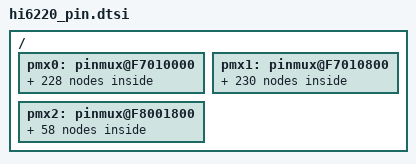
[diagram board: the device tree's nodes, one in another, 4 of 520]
/*****************************************
Generated Time : 2014-07-14-19-44
Author         : s00249479
Tool Version   : V1.0
*****************************************/
/ {
    pmx0: pinmux@F7010000 {
		gpio080_pmx_func: gpio080_pmx_func {
                     pinctrl-single,pins = <0x0    0x0>;
		};
		gpio080_pmx_idle: gpio080_pmx_idle {
                     pinctrl-single,pins = <0x0    0x0>;
		};

		PMU_SSI_pmx_func: PMU_SSI_pmx_func {
                     pinctrl-single,pins = <0x4    0x0>;
		};
		PMU_SSI_pmx_idle: PMU_SSI_pmx_idle {
                     pinctrl-single,pins = <0x4    0x0>;
		};

		gpio066_pmx_func: gpio066_pmx_func {
                     pinctrl-single,pins = <0x8    0x0>;
		};
		gpio066_pmx_idle: gpio066_pmx_idle {
                     pinctrl-single,pins = <0x8    0x1>;
		};

		gpio067_pmx_func: gpio067_pmx_func {
                     pinctrl-single,pins = <0xC    0x0>;
		};
		gpio067_pmx_idle: gpio067_pmx_idle {
                     pinctrl-single,pins = <0xC    0x1>;
		};

		gpio068_pmx_func: gpio068_pmx_func {
                     pinctrl-single,pins = <0x10    0x0>;
		};
		gpio068_pmx_idle: gpio068_pmx_idle {
                     pinctrl-single,pins = <0x10    0x1>;
		};

		gpio069_pmx_func: gpio069_pmx_func {
                     pinctrl-single,pins = <0x14    0x0>;
		};
		gpio069_pmx_idle: gpio069_pmx_idle {
                     pinctrl-single,pins = <0x14    0x1>;
		};

		gpio070_pmx_func: gpio070_pmx_func {
                     pinctrl-single,pins = <0x18    0x0>;
		};
		gpio070_pmx_idle: gpio070_pmx_idle {
                     pinctrl-single,pins = <0x18    0x1>;
		};

		gpio071_pmx_func: gpio071_pmx_func {
                     pinctrl-single,pins = <0x1C    0x0>;
		};
		gpio071_pmx_idle: gpio071_pmx_idle {
                     pinctrl-single,pins = <0x1C    0x1>;
		};

		gpio072_pmx_func: gpio072_pmx_func {
                     pinctrl-single,pins = <0x20    0x0>;
		};
		gpio072_pmx_idle: gpio072_pmx_idle {
                     pinctrl-single,pins = <0x20    0x1>;
		};

		gpio073_pmx_func: gpio073_pmx_func {
                     pinctrl-single,pins = <0x24    0x0>;
		};
		gpio073_pmx_idle: gpio073_pmx_idle {
                     pinctrl-single,pins = <0x24    0x0>;
		};

		gpio074_pmx_func: gpio074_pmx_func {
                     pinctrl-single,pins = <0x28    0x0>;
		};
		gpio074_pmx_idle: gpio074_pmx_idle {
                     pinctrl-single,pins = <0x28    0x0>;
		};

		gpio075_pmx_func: gpio075_pmx_func {
                     pinctrl-single,pins = <0x2C    0x0>;
		};
		gpio075_pmx_idle: gpio075_pmx_idle {
                     pinctrl-single,pins = <0x2C    0x0>;
		};

		gpio076_pmx_func: gpio076_pmx_func {
                     pinctrl-single,pins = <0x30    0x1>;
		};
		gpio076_pmx_idle: gpio076_pmx_idle {
                     pinctrl-single,pins = <0x30    0x1>;
		};

		gpio077_pmx_func: gpio077_pmx_func {
                     pinctrl-single,pins = <0x34    0x1>;
		};
		gpio077_pmx_idle: gpio077_pmx_idle {
                     pinctrl-single,pins = <0x34    0x1>;
		};

		gpio078_pmx_func: gpio078_pmx_func {
                     pinctrl-single,pins = <0x38    0x1>;
		};
		gpio078_pmx_idle: gpio078_pmx_idle {
                     pinctrl-single,pins = <0x38    0x1>;
		};

		gpio079_pmx_func: gpio079_pmx_func {
                     pinctrl-single,pins = <0x3C    0x0>;
		};
		gpio079_pmx_idle: gpio079_pmx_idle {
                     pinctrl-single,pins = <0x3C    0x0>;
		};

		gpio081_pmx_func: gpio081_pmx_func {
                     pinctrl-single,pins = <0x40    0x0>;
		};
		gpio081_pmx_idle: gpio081_pmx_idle {
                     pinctrl-single,pins = <0x40    0x0>;
		};

		gpio082_pmx_func: gpio082_pmx_func {
                     pinctrl-single,pins = <0x44    0x0>;
		};
		gpio082_pmx_idle: gpio082_pmx_idle {
                     pinctrl-single,pins = <0x44    0x0>;
		};

		gpio083_pmx_func: gpio083_pmx_func {
                     pinctrl-single,pins = <0x48    0x0>;
		};
		gpio083_pmx_idle: gpio083_pmx_idle {
                     pinctrl-single,pins = <0x48    0x0>;
		};

		gpio084_pmx_func: gpio084_pmx_func {
                     pinctrl-single,pins = <0x4C    0x1>;
		};
		gpio084_pmx_idle: gpio084_pmx_idle {
                     pinctrl-single,pins = <0x4C    0x1>;
		};

		gpio085_pmx_func: gpio085_pmx_func {
                     pinctrl-single,pins = <0x50    0x1>;
		};
		gpio085_pmx_idle: gpio085_pmx_idle {
                     pinctrl-single,pins = <0x50    0x1>;
		};

		gpio086_pmx_func: gpio086_pmx_func {
                     pinctrl-single,pins = <0x54    0x0>;
		};
		gpio086_pmx_idle: gpio086_pmx_idle {
                     pinctrl-single,pins = <0x54    0x0>;
		};

		gpio087_pmx_func: gpio087_pmx_func {
                     pinctrl-single,pins = <0x58    0x0>;
		};
		gpio087_pmx_idle: gpio087_pmx_idle {
                     pinctrl-single,pins = <0x58    0x0>;
		};

		gpio088_pmx_func: gpio088_pmx_func {
                     pinctrl-single,pins = <0x5C    0x0>;
		};
		gpio088_pmx_idle: gpio088_pmx_idle {
                     pinctrl-single,pins = <0x5C    0x0>;
		};

		gpio089_pmx_func: gpio089_pmx_func {
                     pinctrl-single,pins = <0x60    0x0>;
		};
		gpio089_pmx_idle: gpio089_pmx_idle {
                     pinctrl-single,pins = <0x60    0x0>;
		};

		gpio090_pmx_func: gpio090_pmx_func {
                     pinctrl-single,pins = <0x64    0x1>;
		};
		gpio090_pmx_idle: gpio090_pmx_idle {
                     pinctrl-single,pins = <0x64    0x1>;
		};

		HKADC_SSI_pmx_func: HKADC_SSI_pmx_func {
                     pinctrl-single,pins = <0x68    0x0>;
		};
		HKADC_SSI_pmx_idle: HKADC_SSI_pmx_idle {
                     pinctrl-single,pins = <0x68    0x0>;
		};

		CODEC_CLK_pmx_func: CODEC_CLK_pmx_func {
                     pinctrl-single,pins = <0x6C    0x0>;
		};
		CODEC_CLK_pmx_idle: CODEC_CLK_pmx_idle {
                     pinctrl-single,pins = <0x6C    0x0>;
		};

		gpio091_pmx_func: gpio091_pmx_func {
                     pinctrl-single,pins = <0x70    0x1>;
		};
		gpio091_pmx_idle: gpio091_pmx_idle {
                     pinctrl-single,pins = <0x70    0x1>;
		};

		gpio092_pmx_func: gpio092_pmx_func {
                     pinctrl-single,pins = <0x74    0x0>;
		};
		gpio092_pmx_idle: gpio092_pmx_idle {
                     pinctrl-single,pins = <0x74    0x0>;
		};

		gpio093_pmx_func: gpio093_pmx_func {
                     pinctrl-single,pins = <0x78    0x0>;
		};
		gpio093_pmx_idle: gpio093_pmx_idle {
                     pinctrl-single,pins = <0x78    0x0>;
		};

		gpio094_pmx_func: gpio094_pmx_func {
                     pinctrl-single,pins = <0x7C    0x0>;
		};
		gpio094_pmx_idle: gpio094_pmx_idle {
                     pinctrl-single,pins = <0x7C    0x0>;
		};

		gpio095_pmx_func: gpio095_pmx_func {
                     pinctrl-single,pins = <0x80    0x1>;
		};
		gpio095_pmx_idle: gpio095_pmx_idle {
                     pinctrl-single,pins = <0x80    0x1>;
		};

		gpio096_pmx_func: gpio096_pmx_func {
                     pinctrl-single,pins = <0x84    0x1>;
		};
		gpio096_pmx_idle: gpio096_pmx_idle {
                     pinctrl-single,pins = <0x84    0x1>;
		};

		gpio097_pmx_func: gpio097_pmx_func {
                     pinctrl-single,pins = <0x88    0x1>;
		};
		gpio097_pmx_idle: gpio097_pmx_idle {
                     pinctrl-single,pins = <0x88    0x1>;
		};

		gpio098_pmx_func: gpio098_pmx_func {
                     pinctrl-single,pins = <0x8C    0x1>;
		};
		gpio098_pmx_idle: gpio098_pmx_idle {
                     pinctrl-single,pins = <0x8C    0x1>;
		};

		BT_XCLK_pmx_func: BT_XCLK_pmx_func {
                     pinctrl-single,pins = <0x90    0x0>;
		};
		BT_XCLK_pmx_idle: BT_XCLK_pmx_idle {
                     pinctrl-single,pins = <0x90    0x0>;
		};

		BT_XFS_pmx_func: BT_XFS_pmx_func {
                     pinctrl-single,pins = <0x94    0x0>;
		};
		BT_XFS_pmx_idle: BT_XFS_pmx_idle {
                     pinctrl-single,pins = <0x94    0x0>;
		};

		BT_DI_pmx_func: BT_DI_pmx_func {
                     pinctrl-single,pins = <0x98    0x0>;
		};
		BT_DI_pmx_idle: BT_DI_pmx_idle {
                     pinctrl-single,pins = <0x98    0x0>;
		};

		BT_DO_pmx_func: BT_DO_pmx_func {
                     pinctrl-single,pins = <0x9C    0x0>;
		};
		BT_DO_pmx_idle: BT_DO_pmx_idle {
                     pinctrl-single,pins = <0x9C    0x0>;
		};

		gpio102_pmx_func: gpio102_pmx_func {
                     pinctrl-single,pins = <0xB8    0x1>;
		};
		gpio102_pmx_idle: gpio102_pmx_idle {
                     pinctrl-single,pins = <0xB8    0x1>;
		};

		gpio103_pmx_func: gpio103_pmx_func {
                     pinctrl-single,pins = <0xBC    0x1>;
		};
		gpio103_pmx_idle: gpio103_pmx_idle {
                     pinctrl-single,pins = <0xBC    0x1>;
		};

		gpio104_pmx_func: gpio104_pmx_func {
                     pinctrl-single,pins = <0xC0    0x0>;
		};
		gpio104_pmx_idle: gpio104_pmx_idle {
                     pinctrl-single,pins = <0xC0    0x0>;
		};

		gpio105_pmx_func: gpio105_pmx_func {
                     pinctrl-single,pins = <0xC4    0x0>;
		};
		gpio105_pmx_idle: gpio105_pmx_idle {
                     pinctrl-single,pins = <0xC4    0x0>;
		};

		gpio106_pmx_func: gpio106_pmx_func {
                     pinctrl-single,pins = <0xC8    0x0>;
		};
		gpio106_pmx_idle: gpio106_pmx_idle {
                     pinctrl-single,pins = <0xC8    0x0>;
		};

		gpio107_pmx_func: gpio107_pmx_func {
                     pinctrl-single,pins = <0xCC    0x0>;
		};
		gpio107_pmx_idle: gpio107_pmx_idle {
                     pinctrl-single,pins = <0xCC    0x0>;
		};

		gpio108_pmx_func: gpio108_pmx_func {
                     pinctrl-single,pins = <0xD0    0x0>;
		};
		gpio108_pmx_idle: gpio108_pmx_idle {
                     pinctrl-single,pins = <0xD0    0x0>;
		};

		gpio109_pmx_func: gpio109_pmx_func {
                     pinctrl-single,pins = <0xD4    0x0>;
		};
		gpio109_pmx_idle: gpio109_pmx_idle {
                     pinctrl-single,pins = <0xD4    0x0>;
		};

		gpio110_pmx_func: gpio110_pmx_func {
                     pinctrl-single,pins = <0xD8    0x0>;
		};
		gpio110_pmx_idle: gpio110_pmx_idle {
                     pinctrl-single,pins = <0xD8    0x0>;
		};

		gpio111_pmx_func: gpio111_pmx_func {
                     pinctrl-single,pins = <0xDC    0x0>;
		};
		gpio111_pmx_idle: gpio111_pmx_idle {
                     pinctrl-single,pins = <0xDC    0x0>;
		};

		gpio112_pmx_func: gpio112_pmx_func {
                     pinctrl-single,pins = <0xE0    0x0>;
		};
		gpio112_pmx_idle: gpio112_pmx_idle {
                     pinctrl-single,pins = <0xE0    0x0>;
		};

		gpio113_pmx_func: gpio113_pmx_func {
                     pinctrl-single,pins = <0xE4    0x0>;
		};
		gpio113_pmx_idle: gpio113_pmx_idle {
                     pinctrl-single,pins = <0xE4    0x0>;
		};

		gpio114_pmx_func: gpio114_pmx_func {
                     pinctrl-single,pins = <0xE8    0x0>;
		};
		gpio114_pmx_idle: gpio114_pmx_idle {
                     pinctrl-single,pins = <0xE8    0x0>;
		};

		gpio115_pmx_func: gpio115_pmx_func {
                     pinctrl-single,pins = <0xEC    0x0>;
		};
		gpio115_pmx_idle: gpio115_pmx_idle {
                     pinctrl-single,pins = <0xEC    0x0>;
		};

		gpio116_pmx_func: gpio116_pmx_func {
                     pinctrl-single,pins = <0xF0    0x0>;
		};
		gpio116_pmx_idle: gpio116_pmx_idle {
                     pinctrl-single,pins = <0xF0    0x0>;
		};

		gpio117_pmx_func: gpio117_pmx_func {
                     pinctrl-single,pins = <0xF4    0x0>;
		};
		gpio117_pmx_idle: gpio117_pmx_idle {
                     pinctrl-single,pins = <0xF4    0x0>;
		};

		gpio118_pmx_func: gpio118_pmx_func {
                     pinctrl-single,pins = <0xF8    0x0>;
		};
		gpio118_pmx_idle: gpio118_pmx_idle {
                     pinctrl-single,pins = <0xF8    0x0>;
		};

		gpio119_pmx_func: gpio119_pmx_func {
                     pinctrl-single,pins = <0xFC    0x0>;
		};
		gpio119_pmx_idle: gpio119_pmx_idle {
                     pinctrl-single,pins = <0xFC    0x0>;
		};

		EMMC_CLK_pmx_func: EMMC_CLK_pmx_func {
                     pinctrl-single,pins = <0x100    0x0>;
		};
		EMMC_CLK_pmx_idle: EMMC_CLK_pmx_idle {
                     pinctrl-single,pins = <0x100    0x0>;
		};

		EMMC_CMD_pmx_func: EMMC_CMD_pmx_func {
                     pinctrl-single,pins = <0x104    0x0>;
		};
		EMMC_CMD_pmx_idle: EMMC_CMD_pmx_idle {
                     pinctrl-single,pins = <0x104    0x0>;
		};

		EMMC_DATA0_pmx_func: EMMC_DATA0_pmx_func {
                     pinctrl-single,pins = <0x108    0x0>;
		};
		EMMC_DATA0_pmx_idle: EMMC_DATA0_pmx_idle {
                     pinctrl-single,pins = <0x108    0x0>;
		};

		EMMC_DATA1_pmx_func: EMMC_DATA1_pmx_func {
                     pinctrl-single,pins = <0x10C    0x0>;
		};
		EMMC_DATA1_pmx_idle: EMMC_DATA1_pmx_idle {
                     pinctrl-single,pins = <0x10C    0x0>;
		};

		EMMC_DATA2_pmx_func: EMMC_DATA2_pmx_func {
                     pinctrl-single,pins = <0x110    0x0>;
		};
		EMMC_DATA2_pmx_idle: EMMC_DATA2_pmx_idle {
                     pinctrl-single,pins = <0x110    0x0>;
		};

		EMMC_DATA3_pmx_func: EMMC_DATA3_pmx_func {
                     pinctrl-single,pins = <0x114    0x0>;
		};
		EMMC_DATA3_pmx_idle: EMMC_DATA3_pmx_idle {
                     pinctrl-single,pins = <0x114    0x0>;
		};

		EMMC_DATA4_pmx_func: EMMC_DATA4_pmx_func {
                     pinctrl-single,pins = <0x118    0x0>;
		};
		EMMC_DATA4_pmx_idle: EMMC_DATA4_pmx_idle {
                     pinctrl-single,pins = <0x118    0x0>;
		};

		EMMC_DATA5_pmx_func: EMMC_DATA5_pmx_func {
                     pinctrl-single,pins = <0x11C    0x0>;
		};
		EMMC_DATA5_pmx_idle: EMMC_DATA5_pmx_idle {
                     pinctrl-single,pins = <0x11C    0x0>;
		};

		EMMC_DATA6_pmx_func: EMMC_DATA6_pmx_func {
                     pinctrl-single,pins = <0x120    0x0>;
		};
		EMMC_DATA6_pmx_idle: EMMC_DATA6_pmx_idle {
                     pinctrl-single,pins = <0x120    0x0>;
		};

		EMMC_DATA7_pmx_func: EMMC_DATA7_pmx_func {
                     pinctrl-single,pins = <0x124    0x0>;
		};
		EMMC_DATA7_pmx_idle: EMMC_DATA7_pmx_idle {
                     pinctrl-single,pins = <0x124    0x0>;
		};

		gpio120_pmx_func: gpio120_pmx_func {
                     pinctrl-single,pins = <0x128    0x0>;
		};
		gpio120_pmx_idle: gpio120_pmx_idle {
                     pinctrl-single,pins = <0x128    0x1>;
		};

		gpio121_pmx_func: gpio121_pmx_func {
                     pinctrl-single,pins = <0x12C    0x0>;
		};
		gpio121_pmx_idle: gpio121_pmx_idle {
                     pinctrl-single,pins = <0x12C    0x1>;
		};

		gpio122_pmx_func: gpio122_pmx_func {
                     pinctrl-single,pins = <0x130    0x0>;
		};
		gpio122_pmx_idle: gpio122_pmx_idle {
                     pinctrl-single,pins = <0x130    0x1>;
		};

		gpio123_pmx_func: gpio123_pmx_func {
                     pinctrl-single,pins = <0x134    0x0>;
		};
		gpio123_pmx_idle: gpio123_pmx_idle {
                     pinctrl-single,pins = <0x134    0x1>;
		};

		gpio124_pmx_func: gpio124_pmx_func {
                     pinctrl-single,pins = <0x138    0x0>;
		};
		gpio124_pmx_idle: gpio124_pmx_idle {
                     pinctrl-single,pins = <0x138    0x1>;
		};

		gpio125_pmx_func: gpio125_pmx_func {
                     pinctrl-single,pins = <0x13C    0x0>;
		};
		gpio125_pmx_idle: gpio125_pmx_idle {
                     pinctrl-single,pins = <0x13C    0x1>;
		};

		gpio024_pmx_func: gpio024_pmx_func {
                     pinctrl-single,pins = <0x140    0x0>;
		};
		gpio024_pmx_idle: gpio024_pmx_idle {
                     pinctrl-single,pins = <0x140    0x0>;
		};

		gpio025_pmx_func: gpio025_pmx_func {
                     pinctrl-single,pins = <0x144    0x0>;
		};
		gpio025_pmx_idle: gpio025_pmx_idle {
                     pinctrl-single,pins = <0x144    0x0>;
		};

		gpio026_pmx_func: gpio026_pmx_func {
                     pinctrl-single,pins = <0x148    0x0>;
		};
		gpio026_pmx_idle: gpio026_pmx_idle {
                     pinctrl-single,pins = <0x148    0x0>;
		};

		gpio027_pmx_func: gpio027_pmx_func {
                     pinctrl-single,pins = <0x14C    0x0>;
		};
		gpio027_pmx_idle: gpio027_pmx_idle {
                     pinctrl-single,pins = <0x14C    0x0>;
		};

		gpio028_pmx_func: gpio028_pmx_func {
                     pinctrl-single,pins = <0x150    0x1>;
		};
		gpio028_pmx_idle: gpio028_pmx_idle {
                     pinctrl-single,pins = <0x150    0x1>;
		};

		gpio029_pmx_func: gpio029_pmx_func {
                     pinctrl-single,pins = <0x154    0x0>;
		};
		gpio029_pmx_idle: gpio029_pmx_idle {
                     pinctrl-single,pins = <0x154    0x0>;
		};

		gpio030_pmx_func: gpio030_pmx_func {
                     pinctrl-single,pins = <0x158    0x0>;
		};
		gpio030_pmx_idle: gpio030_pmx_idle {
                     pinctrl-single,pins = <0x158    0x0>;
		};

		gpio031_pmx_func: gpio031_pmx_func {
                     pinctrl-single,pins = <0x15C    0x0>;
		};
		gpio031_pmx_idle: gpio031_pmx_idle {
                     pinctrl-single,pins = <0x15C    0x0>;
		};

		gpio032_pmx_func: gpio032_pmx_func {
                     pinctrl-single,pins = <0x160    0x0>;
		};
		gpio032_pmx_idle: gpio032_pmx_idle {
                     pinctrl-single,pins = <0x160    0x0>;
		};

		gpio033_pmx_func: gpio033_pmx_func {
                     pinctrl-single,pins = <0x164    0x0>;
		};
		gpio033_pmx_idle: gpio033_pmx_idle {
                     pinctrl-single,pins = <0x164    0x0>;
		};

		gpio034_pmx_func: gpio034_pmx_func {
                     pinctrl-single,pins = <0x168    0x0>;
		};
		gpio034_pmx_idle: gpio034_pmx_idle {
                     pinctrl-single,pins = <0x168    0x0>;
		};

		gpio035_pmx_func: gpio035_pmx_func {
                     pinctrl-single,pins = <0x16C    0x0>;
		};
		gpio035_pmx_idle: gpio035_pmx_idle {
                     pinctrl-single,pins = <0x16C    0x0>;
		};

		gpio036_pmx_func: gpio036_pmx_func {
                     pinctrl-single,pins = <0x170    0x1>;
		};
		gpio036_pmx_idle: gpio036_pmx_idle {
                     pinctrl-single,pins = <0x170    0x1>;
		};

		gpio037_pmx_func: gpio037_pmx_func {
                     pinctrl-single,pins = <0x174    0x1>;
		};
		gpio037_pmx_idle: gpio037_pmx_idle {
                     pinctrl-single,pins = <0x174    0x1>;
		};

		gpio038_pmx_func: gpio038_pmx_func {
                     pinctrl-single,pins = <0x178    0x1>;
		};
		gpio038_pmx_idle: gpio038_pmx_idle {
                     pinctrl-single,pins = <0x178    0x1>;
		};

		gpio039_pmx_func: gpio039_pmx_func {
                     pinctrl-single,pins = <0x17C    0x0>;
		};
		gpio039_pmx_idle: gpio039_pmx_idle {
                     pinctrl-single,pins = <0x17C    0x0>;
		};

		gpio040_pmx_func: gpio040_pmx_func {
                     pinctrl-single,pins = <0x180    0x0>;
		};
		gpio040_pmx_idle: gpio040_pmx_idle {
                     pinctrl-single,pins = <0x180    0x0>;
		};

		gpio041_pmx_func: gpio041_pmx_func {
                     pinctrl-single,pins = <0x184    0x0>;
		};
		gpio041_pmx_idle: gpio041_pmx_idle {
                     pinctrl-single,pins = <0x184    0x0>;
		};

		gpio042_pmx_func: gpio042_pmx_func {
                     pinctrl-single,pins = <0x188    0x0>;
		};
		gpio042_pmx_idle: gpio042_pmx_idle {
                     pinctrl-single,pins = <0x188    0x0>;
		};

		gpio043_pmx_func: gpio043_pmx_func {
                     pinctrl-single,pins = <0x18C    0x0>;
		};
		gpio043_pmx_idle: gpio043_pmx_idle {
                     pinctrl-single,pins = <0x18C    0x0>;
		};

		gpio044_pmx_func: gpio044_pmx_func {
                     pinctrl-single,pins = <0x190    0x3>;
		};
		gpio044_pmx_idle: gpio044_pmx_idle {
                     pinctrl-single,pins = <0x190    0x3>;
		};

		gpio045_pmx_func: gpio045_pmx_func {
                     pinctrl-single,pins = <0x194    0x0>;
		};
		gpio045_pmx_idle: gpio045_pmx_idle {
                     pinctrl-single,pins = <0x194    0x0>;
		};

		gpio046_pmx_func: gpio046_pmx_func {
                     pinctrl-single,pins = <0x198    0x0>;
		};
		gpio046_pmx_idle: gpio046_pmx_idle {
                     pinctrl-single,pins = <0x198    0x0>;
		};

		gpio047_pmx_func: gpio047_pmx_func {
                     pinctrl-single,pins = <0x19C    0x0>;
		};
		gpio047_pmx_idle: gpio047_pmx_idle {
                     pinctrl-single,pins = <0x19C    0x0>;
		};

		gpio048_pmx_func: gpio048_pmx_func {
                     pinctrl-single,pins = <0x1A0    0x0>;
		};
		gpio048_pmx_idle: gpio048_pmx_idle {
                     pinctrl-single,pins = <0x1A0    0x0>;
		};

		gpio049_pmx_func: gpio049_pmx_func {
                     pinctrl-single,pins = <0x1A4    0x0>;
		};
		gpio049_pmx_idle: gpio049_pmx_idle {
                     pinctrl-single,pins = <0x1A4    0x0>;
		};

		gpio050_pmx_func: gpio050_pmx_func {
                     pinctrl-single,pins = <0x1A8    0x0>;
		};
		gpio050_pmx_idle: gpio050_pmx_idle {
                     pinctrl-single,pins = <0x1A8    0x0>;
		};

		gpio051_pmx_func: gpio051_pmx_func {
                     pinctrl-single,pins = <0x1AC    0x0>;
		};
		gpio051_pmx_idle: gpio051_pmx_idle {
                     pinctrl-single,pins = <0x1AC    0x0>;
		};

		gpio052_pmx_func: gpio052_pmx_func {
                     pinctrl-single,pins = <0x1B0    0x3>;
		};
		gpio052_pmx_idle: gpio052_pmx_idle {
                     pinctrl-single,pins = <0x1B0    0x3>;
		};

		gpio053_pmx_func: gpio053_pmx_func {
                     pinctrl-single,pins = <0x1B4    0x1>;
		};
		gpio053_pmx_idle: gpio053_pmx_idle {
                     pinctrl-single,pins = <0x1B4    0x1>;
		};

		gpio054_pmx_func: gpio054_pmx_func {
                     pinctrl-single,pins = <0x1B8    0x0>;
		};
		gpio054_pmx_idle: gpio054_pmx_idle {
                     pinctrl-single,pins = <0x1B8    0x0>;
		};

		gpio055_pmx_func: gpio055_pmx_func {
                     pinctrl-single,pins = <0x1BC    0x0>;
		};
		gpio055_pmx_idle: gpio055_pmx_idle {
                     pinctrl-single,pins = <0x1BC    0x0>;
		};

		gpio056_pmx_func: gpio056_pmx_func {
                     pinctrl-single,pins = <0x1C0    0x0>;
		};
		gpio056_pmx_idle: gpio056_pmx_idle {
                     pinctrl-single,pins = <0x1C0    0x0>;
		};

		gpio057_pmx_func: gpio057_pmx_func {
                     pinctrl-single,pins = <0x1C4    0x0>;
		};
		gpio057_pmx_idle: gpio057_pmx_idle {
                     pinctrl-single,pins = <0x1C4    0x0>;
		};

		gpio060_pmx_func: gpio060_pmx_func {
                     pinctrl-single,pins = <0x1D0    0x0>;
		};
		gpio060_pmx_idle: gpio060_pmx_idle {
                     pinctrl-single,pins = <0x1D0    0x0>;
		};

		gpio061_pmx_func: gpio061_pmx_func {
                     pinctrl-single,pins = <0x1D4    0x0>;
		};
		gpio061_pmx_idle: gpio061_pmx_idle {
                     pinctrl-single,pins = <0x1D4    0x0>;
		};

		gpio062_pmx_func: gpio062_pmx_func {
                     pinctrl-single,pins = <0x1D8    0x1>;
		};
		gpio062_pmx_idle: gpio062_pmx_idle {
                     pinctrl-single,pins = <0x1D8    0x1>;
		};

		gpio063_pmx_func: gpio063_pmx_func {
                     pinctrl-single,pins = <0x1DC    0x1>;
		};
		gpio063_pmx_idle: gpio063_pmx_idle {
                     pinctrl-single,pins = <0x1DC    0x1>;
		};

		gpio064_pmx_func: gpio064_pmx_func {
                     pinctrl-single,pins = <0x1E0    0x0>;
		};
		gpio064_pmx_idle: gpio064_pmx_idle {
                     pinctrl-single,pins = <0x1E0    0x0>;
		};

		gpio065_pmx_func: gpio065_pmx_func {
                     pinctrl-single,pins = <0x1E4    0x0>;
		};
		gpio065_pmx_idle: gpio065_pmx_idle {
                     pinctrl-single,pins = <0x1E4    0x0>;
		};

       };

    pmx1: pinmux@F7010800 {
		gpio080_cfg_func: gpio080_cfg_func {
                     pinctrl-single,pins = <0x0  0>;
                     pinctrl-single,bias-pulldown = <0 2 0 2>;
                     pinctrl-single,bias-pullup = <1 1 0 1>;
                     pinctrl-single,drive-strength = <0x00 0x70>;
		};
		gpio080_cfg_idle: gpio080_cfg_idle {
                     pinctrl-single,pins = <0x0  0>;
                     pinctrl-single,bias-pulldown = <0 2 0 2>;
                     pinctrl-single,bias-pullup = <1 1 0 1>;
                     pinctrl-single,drive-strength = <0x00 0x70>;
		};

		PMU_SSI_cfg_func: PMU_SSI_cfg_func {
                     pinctrl-single,pins = <0x4  0>;
                     pinctrl-single,bias-pulldown = <0 2 0 2>;
                     pinctrl-single,bias-pullup = <0 1 0 1>;
                     pinctrl-single,drive-strength = <0x00 0x70>;
		};
		PMU_SSI_cfg_idle: PMU_SSI_cfg_idle {
                     pinctrl-single,pins = <0x4  0>;
                     pinctrl-single,bias-pulldown = <0 2 0 2>;
                     pinctrl-single,bias-pullup = <0 1 0 1>;
                     pinctrl-single,drive-strength = <0x00 0x70>;
		};

		gpio066_cfg_func: gpio066_cfg_func {
                     pinctrl-single,pins = <0x8  0>;
                     pinctrl-single,bias-pulldown = <0 2 0 2>;
                     pinctrl-single,bias-pullup = <0 1 0 1>;
                     pinctrl-single,drive-strength = <0x00 0x70>;
		};
		gpio066_cfg_idle: gpio066_cfg_idle {
                     pinctrl-single,pins = <0x8  0>;
                     pinctrl-single,bias-pulldown = <2 2 0 2>;
                     pinctrl-single,bias-pullup = <0 1 0 1>;
                     pinctrl-single,drive-strength = <0x00 0x70>;
		};

		gpio067_cfg_func: gpio067_cfg_func {
                     pinctrl-single,pins = <0xC  0>;
                     pinctrl-single,bias-pulldown = <0 2 0 2>;
                     pinctrl-single,bias-pullup = <0 1 0 1>;
                     pinctrl-single,drive-strength = <0x30 0x70>;
		};
		gpio067_cfg_idle: gpio067_cfg_idle {
                     pinctrl-single,pins = <0xC  0>;
                     pinctrl-single,bias-pulldown = <2 2 0 2>;
                     pinctrl-single,bias-pullup = <0 1 0 1>;
                     pinctrl-single,drive-strength = <0x00 0x70>;
		};

		gpio068_cfg_func: gpio068_cfg_func {
                     pinctrl-single,pins = <0x10  0>;
                     pinctrl-single,bias-pulldown = <0 2 0 2>;
                     pinctrl-single,bias-pullup = <0 1 0 1>;
                     pinctrl-single,drive-strength = <0x20 0x70>;
		};
		gpio068_cfg_idle: gpio068_cfg_idle {
                     pinctrl-single,pins = <0x10  0>;
                     pinctrl-single,bias-pulldown = <2 2 0 2>;
                     pinctrl-single,bias-pullup = <0 1 0 1>;
                     pinctrl-single,drive-strength = <0x00 0x70>;
		};

		gpio069_cfg_func: gpio069_cfg_func {
                     pinctrl-single,pins = <0x14  0>;
                     pinctrl-single,bias-pulldown = <0 2 0 2>;
                     pinctrl-single,bias-pullup = <0 1 0 1>;
                     pinctrl-single,drive-strength = <0x20 0x70>;
		};
		gpio069_cfg_idle: gpio069_cfg_idle {
                     pinctrl-single,pins = <0x14  0>;
                     pinctrl-single,bias-pulldown = <2 2 0 2>;
                     pinctrl-single,bias-pullup = <0 1 0 1>;
                     pinctrl-single,drive-strength = <0x00 0x70>;
		};

		gpio070_cfg_func: gpio070_cfg_func {
                     pinctrl-single,pins = <0x18  0>;
                     pinctrl-single,bias-pulldown = <0 2 0 2>;
                     pinctrl-single,bias-pullup = <0 1 0 1>;
                     pinctrl-single,drive-strength = <0x20 0x70>;
		};
		gpio070_cfg_idle: gpio070_cfg_idle {
                     pinctrl-single,pins = <0x18  0>;
                     pinctrl-single,bias-pulldown = <2 2 0 2>;
                     pinctrl-single,bias-pullup = <0 1 0 1>;
                     pinctrl-single,drive-strength = <0x00 0x70>;
		};

		gpio071_cfg_func: gpio071_cfg_func {
                     pinctrl-single,pins = <0x1C  0>;
                     pinctrl-single,bias-pulldown = <0 2 0 2>;
                     pinctrl-single,bias-pullup = <0 1 0 1>;
                     pinctrl-single,drive-strength = <0x20 0x70>;
		};
		gpio071_cfg_idle: gpio071_cfg_idle {
                     pinctrl-single,pins = <0x1C  0>;
                     pinctrl-single,bias-pulldown = <2 2 0 2>;
                     pinctrl-single,bias-pullup = <0 1 0 1>;
                     pinctrl-single,drive-strength = <0x00 0x70>;
		};

		gpio072_cfg_func: gpio072_cfg_func {
                     pinctrl-single,pins = <0x20  0>;
                     pinctrl-single,bias-pulldown = <0 2 0 2>;
                     pinctrl-single,bias-pullup = <0 1 0 1>;
                     pinctrl-single,drive-strength = <0x20 0x70>;
		};
		gpio072_cfg_idle: gpio072_cfg_idle {
                     pinctrl-single,pins = <0x20  0>;
                     pinctrl-single,bias-pulldown = <2 2 0 2>;
                     pinctrl-single,bias-pullup = <0 1 0 1>;
                     pinctrl-single,drive-strength = <0x00 0x70>;
		};

		gpio073_cfg_func: gpio073_cfg_func {
                     pinctrl-single,pins = <0x28  0>;
                     pinctrl-single,bias-pulldown = <0 2 0 2>;
                     pinctrl-single,bias-pullup = <0 1 0 1>;
                     pinctrl-single,drive-strength = <0x00 0x70>;
		};
		gpio073_cfg_idle: gpio073_cfg_idle {
                     pinctrl-single,pins = <0x28  0>;
                     pinctrl-single,bias-pulldown = <0 2 0 2>;
                     pinctrl-single,bias-pullup = <0 1 0 1>;
                     pinctrl-single,drive-strength = <0x00 0x70>;
		};

		gpio074_cfg_func: gpio074_cfg_func {
                     pinctrl-single,pins = <0x2C  0>;
                     pinctrl-single,bias-pulldown = <0 2 0 2>;
                     pinctrl-single,bias-pullup = <0 1 0 1>;
                     pinctrl-single,drive-strength = <0x00 0x70>;
		};
		gpio074_cfg_idle: gpio074_cfg_idle {
                     pinctrl-single,pins = <0x2C  0>;
                     pinctrl-single,bias-pulldown = <0 2 0 2>;
                     pinctrl-single,bias-pullup = <0 1 0 1>;
                     pinctrl-single,drive-strength = <0x00 0x70>;
		};

		gpio075_cfg_func: gpio075_cfg_func {
                     pinctrl-single,pins = <0x30  0>;
                     pinctrl-single,bias-pulldown = <0 2 0 2>;
                     pinctrl-single,bias-pullup = <0 1 0 1>;
                     pinctrl-single,drive-strength = <0x00 0x70>;
		};
		gpio075_cfg_idle: gpio075_cfg_idle {
                     pinctrl-single,pins = <0x30  0>;
                     pinctrl-single,bias-pulldown = <0 2 0 2>;
                     pinctrl-single,bias-pullup = <0 1 0 1>;
                     pinctrl-single,drive-strength = <0x00 0x70>;
		};

		gpio076_cfg_func: gpio076_cfg_func {
                     pinctrl-single,pins = <0x34  0>;
                     pinctrl-single,bias-pulldown = <0 2 0 2>;
                     pinctrl-single,bias-pullup = <0 1 0 1>;
                     pinctrl-single,drive-strength = <0x00 0x70>;
		};
		gpio076_cfg_idle: gpio076_cfg_idle {
                     pinctrl-single,pins = <0x34  0>;
                     pinctrl-single,bias-pulldown = <2 2 0 2>;
                     pinctrl-single,bias-pullup = <0 1 0 1>;
                     pinctrl-single,drive-strength = <0x00 0x70>;
		};

		gpio077_cfg_func: gpio077_cfg_func {
                     pinctrl-single,pins = <0x38  0>;
                     pinctrl-single,bias-pulldown = <0 2 0 2>;
                     pinctrl-single,bias-pullup = <0 1 0 1>;
                     pinctrl-single,drive-strength = <0x00 0x70>;
		};
		gpio077_cfg_idle: gpio077_cfg_idle {
                     pinctrl-single,pins = <0x38  0>;
                     pinctrl-single,bias-pulldown = <2 2 0 2>;
                     pinctrl-single,bias-pullup = <0 1 0 1>;
                     pinctrl-single,drive-strength = <0x00 0x70>;
		};

		gpio078_cfg_func: gpio078_cfg_func {
                     pinctrl-single,pins = <0x3C  0>;
                     pinctrl-single,bias-pulldown = <0 2 0 2>;
                     pinctrl-single,bias-pullup = <0 1 0 1>;
                     pinctrl-single,drive-strength = <0x00 0x70>;
		};
		gpio078_cfg_idle: gpio078_cfg_idle {
                     pinctrl-single,pins = <0x3C  0>;
                     pinctrl-single,bias-pulldown = <0 2 0 2>;
                     pinctrl-single,bias-pullup = <0 1 0 1>;
                     pinctrl-single,drive-strength = <0x00 0x70>;
		};

		gpio079_cfg_func: gpio079_cfg_func {
                     pinctrl-single,pins = <0x40  0>;
                     pinctrl-single,bias-pulldown = <0 2 0 2>;
                     pinctrl-single,bias-pullup = <0 1 0 1>;
                     pinctrl-single,drive-strength = <0x00 0x70>;
		};
		gpio079_cfg_idle: gpio079_cfg_idle {
                     pinctrl-single,pins = <0x40  0>;
                     pinctrl-single,bias-pulldown = <0 2 0 2>;
                     pinctrl-single,bias-pullup = <0 1 0 1>;
                     pinctrl-single,drive-strength = <0x00 0x70>;
		};

		gpio081_cfg_func: gpio081_cfg_func {
                     pinctrl-single,pins = <0x44  0>;
                     pinctrl-single,bias-pulldown = <0 2 0 2>;
                     pinctrl-single,bias-pullup = <0 1 0 1>;
                     pinctrl-single,drive-strength = <0x00 0x70>;
		};
		gpio081_cfg_idle: gpio081_cfg_idle {
                     pinctrl-single,pins = <0x44  0>;
                     pinctrl-single,bias-pulldown = <0 2 0 2>;
                     pinctrl-single,bias-pullup = <0 1 0 1>;
                     pinctrl-single,drive-strength = <0x00 0x70>;
		};

		gpio082_cfg_func: gpio082_cfg_func {
                     pinctrl-single,pins = <0x48  0>;
                     pinctrl-single,bias-pulldown = <0 2 0 2>;
                     pinctrl-single,bias-pullup = <0 1 0 1>;
                     pinctrl-single,drive-strength = <0x00 0x70>;
		};
		gpio082_cfg_idle: gpio082_cfg_idle {
                     pinctrl-single,pins = <0x48  0>;
                     pinctrl-single,bias-pulldown = <0 2 0 2>;
                     pinctrl-single,bias-pullup = <0 1 0 1>;
                     pinctrl-single,drive-strength = <0x00 0x70>;
		};

		gpio083_cfg_func: gpio083_cfg_func {
                     pinctrl-single,pins = <0x4C  0>;
                     pinctrl-single,bias-pulldown = <0 2 0 2>;
                     pinctrl-single,bias-pullup = <0 1 0 1>;
                     pinctrl-single,drive-strength = <0x00 0x70>;
		};
		gpio083_cfg_idle: gpio083_cfg_idle {
                     pinctrl-single,pins = <0x4C  0>;
                     pinctrl-single,bias-pulldown = <0 2 0 2>;
                     pinctrl-single,bias-pullup = <0 1 0 1>;
                     pinctrl-single,drive-strength = <0x00 0x70>;
		};

		gpio084_cfg_func: gpio084_cfg_func {
                     pinctrl-single,pins = <0x50  0>;
                     pinctrl-single,bias-pulldown = <0 2 0 2>;
                     pinctrl-single,bias-pullup = <0 1 0 1>;
                     pinctrl-single,drive-strength = <0x00 0x70>;
		};
		gpio084_cfg_idle: gpio084_cfg_idle {
                     pinctrl-single,pins = <0x50  0>;
                     pinctrl-single,bias-pulldown = <0 2 0 2>;
                     pinctrl-single,bias-pullup = <0 1 0 1>;
                     pinctrl-single,drive-strength = <0x00 0x70>;
		};

		gpio085_cfg_func: gpio085_cfg_func {
                     pinctrl-single,pins = <0x54  0>;
                     pinctrl-single,bias-pulldown = <2 2 0 2>;
                     pinctrl-single,bias-pullup = <0 1 0 1>;
                     pinctrl-single,drive-strength = <0x00 0x70>;
		};
		gpio085_cfg_idle: gpio085_cfg_idle {
                     pinctrl-single,pins = <0x54  0>;
                     pinctrl-single,bias-pulldown = <2 2 0 2>;
                     pinctrl-single,bias-pullup = <0 1 0 1>;
                     pinctrl-single,drive-strength = <0x00 0x70>;
		};

		gpio086_cfg_func: gpio086_cfg_func {
                     pinctrl-single,pins = <0x58  0>;
                     pinctrl-single,bias-pulldown = <0 2 0 2>;
                     pinctrl-single,bias-pullup = <0 1 0 1>;
                     pinctrl-single,drive-strength = <0x00 0x70>;
		};
		gpio086_cfg_idle: gpio086_cfg_idle {
                     pinctrl-single,pins = <0x58  0>;
                     pinctrl-single,bias-pulldown = <0 2 0 2>;
                     pinctrl-single,bias-pullup = <0 1 0 1>;
                     pinctrl-single,drive-strength = <0x00 0x70>;
		};

		gpio087_cfg_func: gpio087_cfg_func {
                     pinctrl-single,pins = <0x5C  0>;
                     pinctrl-single,bias-pulldown = <0 2 0 2>;
                     pinctrl-single,bias-pullup = <0 1 0 1>;
                     pinctrl-single,drive-strength = <0x00 0x70>;
		};
		gpio087_cfg_idle: gpio087_cfg_idle {
                     pinctrl-single,pins = <0x5C  0>;
                     pinctrl-single,bias-pulldown = <0 2 0 2>;
                     pinctrl-single,bias-pullup = <0 1 0 1>;
                     pinctrl-single,drive-strength = <0x00 0x70>;
		};

		gpio088_cfg_func: gpio088_cfg_func {
                     pinctrl-single,pins = <0x60  0>;
                     pinctrl-single,bias-pulldown = <0 2 0 2>;
                     pinctrl-single,bias-pullup = <0 1 0 1>;
                     pinctrl-single,drive-strength = <0x00 0x70>;
		};
		gpio088_cfg_idle: gpio088_cfg_idle {
                     pinctrl-single,pins = <0x60  0>;
                     pinctrl-single,bias-pulldown = <0 2 0 2>;
                     pinctrl-single,bias-pullup = <0 1 0 1>;
                     pinctrl-single,drive-strength = <0x00 0x70>;
		};

		gpio089_cfg_func: gpio089_cfg_func {
                     pinctrl-single,pins = <0x64  0>;
                     pinctrl-single,bias-pulldown = <0 2 0 2>;
                     pinctrl-single,bias-pullup = <0 1 0 1>;
                     pinctrl-single,drive-strength = <0x00 0x70>;
		};
		gpio089_cfg_idle: gpio089_cfg_idle {
                     pinctrl-single,pins = <0x64  0>;
                     pinctrl-single,bias-pulldown = <0 2 0 2>;
                     pinctrl-single,bias-pullup = <0 1 0 1>;
                     pinctrl-single,drive-strength = <0x00 0x70>;
		};

		gpio090_cfg_func: gpio090_cfg_func {
                     pinctrl-single,pins = <0x68  0>;
                     pinctrl-single,bias-pulldown = <2 2 0 2>;
                     pinctrl-single,bias-pullup = <0 1 0 1>;
                     pinctrl-single,drive-strength = <0x00 0x70>;
		};
		gpio090_cfg_idle: gpio090_cfg_idle {
                     pinctrl-single,pins = <0x68  0>;
                     pinctrl-single,bias-pulldown = <2 2 0 2>;
                     pinctrl-single,bias-pullup = <0 1 0 1>;
                     pinctrl-single,drive-strength = <0x00 0x70>;
		};

		HKADC_SSI_cfg_func: HKADC_SSI_cfg_func {
                     pinctrl-single,pins = <0x6C  0>;
                     pinctrl-single,bias-pulldown = <0 2 0 2>;
                     pinctrl-single,bias-pullup = <0 1 0 1>;
                     pinctrl-single,drive-strength = <0x00 0x70>;
		};
		HKADC_SSI_cfg_idle: HKADC_SSI_cfg_idle {
                     pinctrl-single,pins = <0x6C  0>;
                     pinctrl-single,bias-pulldown = <0 2 0 2>;
                     pinctrl-single,bias-pullup = <0 1 0 1>;
                     pinctrl-single,drive-strength = <0x00 0x70>;
		};

		CODEC_CLK_cfg_func: CODEC_CLK_cfg_func {
                     pinctrl-single,pins = <0x70  0>;
                     pinctrl-single,bias-pulldown = <0 2 0 2>;
                     pinctrl-single,bias-pullup = <0 1 0 1>;
                     pinctrl-single,drive-strength = <0x10 0x70>;
		};
		CODEC_CLK_cfg_idle: CODEC_CLK_cfg_idle {
                     pinctrl-single,pins = <0x70  0>;
                     pinctrl-single,bias-pulldown = <0 2 0 2>;
                     pinctrl-single,bias-pullup = <0 1 0 1>;
                     pinctrl-single,drive-strength = <0x00 0x70>;
		};

		gpio091_cfg_func: gpio091_cfg_func {
                     pinctrl-single,pins = <0x74  0>;
                     pinctrl-single,bias-pulldown = <2 2 0 2>;
                     pinctrl-single,bias-pullup = <0 1 0 1>;
                     pinctrl-single,drive-strength = <0x00 0x70>;
		};
		gpio091_cfg_idle: gpio091_cfg_idle {
                     pinctrl-single,pins = <0x74  0>;
                     pinctrl-single,bias-pulldown = <2 2 0 2>;
                     pinctrl-single,bias-pullup = <0 1 0 1>;
                     pinctrl-single,drive-strength = <0x00 0x70>;
		};

		gpio092_cfg_func: gpio092_cfg_func {
                     pinctrl-single,pins = <0x78  0>;
                     pinctrl-single,bias-pulldown = <0 2 0 2>;
                     pinctrl-single,bias-pullup = <0 1 0 1>;
                     pinctrl-single,drive-strength = <0x10 0x70>;
		};
		gpio092_cfg_idle: gpio092_cfg_idle {
                     pinctrl-single,pins = <0x78  0>;
                     pinctrl-single,bias-pulldown = <0 2 0 2>;
                     pinctrl-single,bias-pullup = <0 1 0 1>;
                     pinctrl-single,drive-strength = <0x00 0x70>;
		};

		gpio093_cfg_func: gpio093_cfg_func {
                     pinctrl-single,pins = <0x7C  0>;
                     pinctrl-single,bias-pulldown = <0 2 0 2>;
                     pinctrl-single,bias-pullup = <0 1 0 1>;
                     pinctrl-single,drive-strength = <0x10 0x70>;
		};
		gpio093_cfg_idle: gpio093_cfg_idle {
                     pinctrl-single,pins = <0x7C  0>;
                     pinctrl-single,bias-pulldown = <0 2 0 2>;
                     pinctrl-single,bias-pullup = <0 1 0 1>;
                     pinctrl-single,drive-strength = <0x00 0x70>;
		};

		gpio094_cfg_func: gpio094_cfg_func {
                     pinctrl-single,pins = <0x80  0>;
                     pinctrl-single,bias-pulldown = <0 2 0 2>;
                     pinctrl-single,bias-pullup = <0 1 0 1>;
                     pinctrl-single,drive-strength = <0x10 0x70>;
		};
		gpio094_cfg_idle: gpio094_cfg_idle {
                     pinctrl-single,pins = <0x80  0>;
                     pinctrl-single,bias-pulldown = <0 2 0 2>;
                     pinctrl-single,bias-pullup = <0 1 0 1>;
                     pinctrl-single,drive-strength = <0x00 0x70>;
		};

		gpio095_cfg_func: gpio095_cfg_func {
                     pinctrl-single,pins = <0x84  0>;
                     pinctrl-single,bias-pulldown = <2 2 0 2>;
                     pinctrl-single,bias-pullup = <0 1 0 1>;
                     pinctrl-single,drive-strength = <0x00 0x70>;
		};
		gpio095_cfg_idle: gpio095_cfg_idle {
                     pinctrl-single,pins = <0x84  0>;
                     pinctrl-single,bias-pulldown = <2 2 0 2>;
                     pinctrl-single,bias-pullup = <0 1 0 1>;
                     pinctrl-single,drive-strength = <0x00 0x70>;
		};

		gpio096_cfg_func: gpio096_cfg_func {
                     pinctrl-single,pins = <0x88  0>;
                     pinctrl-single,bias-pulldown = <2 2 0 2>;
                     pinctrl-single,bias-pullup = <0 1 0 1>;
                     pinctrl-single,drive-strength = <0x00 0x70>;
		};
		gpio096_cfg_idle: gpio096_cfg_idle {
                     pinctrl-single,pins = <0x88  0>;
                     pinctrl-single,bias-pulldown = <2 2 0 2>;
                     pinctrl-single,bias-pullup = <0 1 0 1>;
                     pinctrl-single,drive-strength = <0x00 0x70>;
		};

		gpio097_cfg_func: gpio097_cfg_func {
                     pinctrl-single,pins = <0x8C  0>;
                     pinctrl-single,bias-pulldown = <2 2 0 2>;
                     pinctrl-single,bias-pullup = <0 1 0 1>;
                     pinctrl-single,drive-strength = <0x00 0x70>;
		};
		gpio097_cfg_idle: gpio097_cfg_idle {
                     pinctrl-single,pins = <0x8C  0>;
                     pinctrl-single,bias-pulldown = <2 2 0 2>;
                     pinctrl-single,bias-pullup = <0 1 0 1>;
                     pinctrl-single,drive-strength = <0x00 0x70>;
		};

		gpio098_cfg_func: gpio098_cfg_func {
                     pinctrl-single,pins = <0x90  0>;
                     pinctrl-single,bias-pulldown = <2 2 0 2>;
                     pinctrl-single,bias-pullup = <0 1 0 1>;
                     pinctrl-single,drive-strength = <0x00 0x70>;
		};
		gpio098_cfg_idle: gpio098_cfg_idle {
                     pinctrl-single,pins = <0x90  0>;
                     pinctrl-single,bias-pulldown = <2 2 0 2>;
                     pinctrl-single,bias-pullup = <0 1 0 1>;
                     pinctrl-single,drive-strength = <0x00 0x70>;
		};

		BT_XCLK_cfg_func: BT_XCLK_cfg_func {
                     pinctrl-single,pins = <0x94  0>;
                     pinctrl-single,bias-pulldown = <0 2 0 2>;
                     pinctrl-single,bias-pullup = <0 1 0 1>;
                     pinctrl-single,drive-strength = <0x00 0x70>;
		};
		BT_XCLK_cfg_idle: BT_XCLK_cfg_idle {
                     pinctrl-single,pins = <0x94  0>;
                     pinctrl-single,bias-pulldown = <2 2 0 2>;
                     pinctrl-single,bias-pullup = <0 1 0 1>;
                     pinctrl-single,drive-strength = <0x00 0x70>;
		};

		BT_XFS_cfg_func: BT_XFS_cfg_func {
                     pinctrl-single,pins = <0x98  0>;
                     pinctrl-single,bias-pulldown = <0 2 0 2>;
                     pinctrl-single,bias-pullup = <0 1 0 1>;
                     pinctrl-single,drive-strength = <0x00 0x70>;
		};
		BT_XFS_cfg_idle: BT_XFS_cfg_idle {
                     pinctrl-single,pins = <0x98  0>;
                     pinctrl-single,bias-pulldown = <2 2 0 2>;
                     pinctrl-single,bias-pullup = <0 1 0 1>;
                     pinctrl-single,drive-strength = <0x00 0x70>;
		};

		BT_DI_cfg_func: BT_DI_cfg_func {
                     pinctrl-single,pins = <0x9C  0>;
                     pinctrl-single,bias-pulldown = <0 2 0 2>;
                     pinctrl-single,bias-pullup = <0 1 0 1>;
                     pinctrl-single,drive-strength = <0x00 0x70>;
		};
		BT_DI_cfg_idle: BT_DI_cfg_idle {
                     pinctrl-single,pins = <0x9C  0>;
                     pinctrl-single,bias-pulldown = <2 2 0 2>;
                     pinctrl-single,bias-pullup = <0 1 0 1>;
                     pinctrl-single,drive-strength = <0x00 0x70>;
		};

		BT_DO_cfg_func: BT_DO_cfg_func {
                     pinctrl-single,pins = <0xA0  0>;
                     pinctrl-single,bias-pulldown = <0 2 0 2>;
                     pinctrl-single,bias-pullup = <0 1 0 1>;
                     pinctrl-single,drive-strength = <0x00 0x70>;
		};
		BT_DO_cfg_idle: BT_DO_cfg_idle {
                     pinctrl-single,pins = <0xA0  0>;
                     pinctrl-single,bias-pulldown = <0 2 0 2>;
                     pinctrl-single,bias-pullup = <0 1 0 1>;
                     pinctrl-single,drive-strength = <0x00 0x70>;
		};

		gpio102_cfg_func: gpio102_cfg_func {
                     pinctrl-single,pins = <0xBC  0>;
                     pinctrl-single,bias-pulldown = <2 2 0 2>;
                     pinctrl-single,bias-pullup = <0 1 0 1>;
                     pinctrl-single,drive-strength = <0x00 0x70>;
		};
		gpio102_cfg_idle: gpio102_cfg_idle {
                     pinctrl-single,pins = <0xBC  0>;
                     pinctrl-single,bias-pulldown = <2 2 0 2>;
                     pinctrl-single,bias-pullup = <0 1 0 1>;
                     pinctrl-single,drive-strength = <0x00 0x70>;
		};

		gpio103_cfg_func: gpio103_cfg_func {
                     pinctrl-single,pins = <0xC0  0>;
                     pinctrl-single,bias-pulldown = <2 2 0 2>;
                     pinctrl-single,bias-pullup = <0 1 0 1>;
                     pinctrl-single,drive-strength = <0x00 0x70>;
		};
		gpio103_cfg_idle: gpio103_cfg_idle {
                     pinctrl-single,pins = <0xC0  0>;
                     pinctrl-single,bias-pulldown = <2 2 0 2>;
                     pinctrl-single,bias-pullup = <0 1 0 1>;
                     pinctrl-single,drive-strength = <0x00 0x70>;
		};

		gpio104_cfg_func: gpio104_cfg_func {
                     pinctrl-single,pins = <0xC4  0>;
                     pinctrl-single,bias-pulldown = <0 2 0 2>;
                     pinctrl-single,bias-pullup = <1 1 0 1>;
                     pinctrl-single,drive-strength = <0x00 0x70>;
		};
		gpio104_cfg_idle: gpio104_cfg_idle {
                     pinctrl-single,pins = <0xC4  0>;
                     pinctrl-single,bias-pulldown = <0 2 0 2>;
                     pinctrl-single,bias-pullup = <1 1 0 1>;
                     pinctrl-single,drive-strength = <0x00 0x70>;
		};

		gpio105_cfg_func: gpio105_cfg_func {
                     pinctrl-single,pins = <0xC8  0>;
                     pinctrl-single,bias-pulldown = <0 2 0 2>;
                     pinctrl-single,bias-pullup = <0 1 0 1>;
                     pinctrl-single,drive-strength = <0x10 0x70>;
		};
		gpio105_cfg_idle: gpio105_cfg_idle {
                     pinctrl-single,pins = <0xC8  0>;
                     pinctrl-single,bias-pulldown = <0 2 0 2>;
                     pinctrl-single,bias-pullup = <0 1 0 1>;
                     pinctrl-single,drive-strength = <0x10 0x70>;
		};

		gpio106_cfg_func: gpio106_cfg_func {
                     pinctrl-single,pins = <0xCC  0>;
                     pinctrl-single,bias-pulldown = <0 2 0 2>;
                     pinctrl-single,bias-pullup = <1 1 0 1>;
                     pinctrl-single,drive-strength = <0x00 0x70>;
		};
		gpio106_cfg_idle: gpio106_cfg_idle {
                     pinctrl-single,pins = <0xCC  0>;
                     pinctrl-single,bias-pulldown = <0 2 0 2>;
                     pinctrl-single,bias-pullup = <1 1 0 1>;
                     pinctrl-single,drive-strength = <0x00 0x70>;
		};

		gpio107_cfg_func: gpio107_cfg_func {
                     pinctrl-single,pins = <0xD0  0>;
                     pinctrl-single,bias-pulldown = <0 2 0 2>;
                     pinctrl-single,bias-pullup = <0 1 0 1>;
                     pinctrl-single,drive-strength = <0x00 0x70>;
		};
		gpio107_cfg_idle: gpio107_cfg_idle {
                     pinctrl-single,pins = <0xD0  0>;
                     pinctrl-single,bias-pulldown = <0 2 0 2>;
                     pinctrl-single,bias-pullup = <0 1 0 1>;
                     pinctrl-single,drive-strength = <0x00 0x70>;
		};

		gpio108_cfg_func: gpio108_cfg_func {
                     pinctrl-single,pins = <0xD4  0>;
                     pinctrl-single,bias-pulldown = <0 2 0 2>;
                     pinctrl-single,bias-pullup = <1 1 0 1>;
                     pinctrl-single,drive-strength = <0x00 0x70>;
		};
		gpio108_cfg_idle: gpio108_cfg_idle {
                     pinctrl-single,pins = <0xD4  0>;
                     pinctrl-single,bias-pulldown = <0 2 0 2>;
                     pinctrl-single,bias-pullup = <1 1 0 1>;
                     pinctrl-single,drive-strength = <0x00 0x70>;
		};

		gpio109_cfg_func: gpio109_cfg_func {
                     pinctrl-single,pins = <0xD8  0>;
                     pinctrl-single,bias-pulldown = <0 2 0 2>;
                     pinctrl-single,bias-pullup = <0 1 0 1>;
                     pinctrl-single,drive-strength = <0x00 0x70>;
		};
		gpio109_cfg_idle: gpio109_cfg_idle {
                     pinctrl-single,pins = <0xD8  0>;
                     pinctrl-single,bias-pulldown = <0 2 0 2>;
                     pinctrl-single,bias-pullup = <0 1 0 1>;
                     pinctrl-single,drive-strength = <0x00 0x70>;
		};

		gpio110_cfg_func: gpio110_cfg_func {
                     pinctrl-single,pins = <0xDC  0>;
                     pinctrl-single,bias-pulldown = <0 2 0 2>;
                     pinctrl-single,bias-pullup = <0 1 0 1>;
                     pinctrl-single,drive-strength = <0x00 0x70>;
		};
		gpio110_cfg_idle: gpio110_cfg_idle {
                     pinctrl-single,pins = <0xDC  0>;
                     pinctrl-single,bias-pulldown = <0 2 0 2>;
                     pinctrl-single,bias-pullup = <0 1 0 1>;
                     pinctrl-single,drive-strength = <0x00 0x70>;
		};

		gpio111_cfg_func: gpio111_cfg_func {
                     pinctrl-single,pins = <0xE0  0>;
                     pinctrl-single,bias-pulldown = <0 2 0 2>;
                     pinctrl-single,bias-pullup = <0 1 0 1>;
                     pinctrl-single,drive-strength = <0x00 0x70>;
		};
		gpio111_cfg_idle: gpio111_cfg_idle {
                     pinctrl-single,pins = <0xE0  0>;
                     pinctrl-single,bias-pulldown = <0 2 0 2>;
                     pinctrl-single,bias-pullup = <0 1 0 1>;
                     pinctrl-single,drive-strength = <0x00 0x70>;
		};

		gpio112_cfg_func: gpio112_cfg_func {
                     pinctrl-single,pins = <0xE4  0>;
                     pinctrl-single,bias-pulldown = <0 2 0 2>;
                     pinctrl-single,bias-pullup = <0 1 0 1>;
                     pinctrl-single,drive-strength = <0x00 0x70>;
		};
		gpio112_cfg_idle: gpio112_cfg_idle {
                     pinctrl-single,pins = <0xE4  0>;
                     pinctrl-single,bias-pulldown = <0 2 0 2>;
                     pinctrl-single,bias-pullup = <0 1 0 1>;
                     pinctrl-single,drive-strength = <0x00 0x70>;
		};

		gpio113_cfg_func: gpio113_cfg_func {
                     pinctrl-single,pins = <0xE8  0>;
                     pinctrl-single,bias-pulldown = <0 2 0 2>;
                     pinctrl-single,bias-pullup = <0 1 0 1>;
                     pinctrl-single,drive-strength = <0x00 0x70>;
		};
		gpio113_cfg_idle: gpio113_cfg_idle {
                     pinctrl-single,pins = <0xE8  0>;
                     pinctrl-single,bias-pulldown = <0 2 0 2>;
                     pinctrl-single,bias-pullup = <0 1 0 1>;
                     pinctrl-single,drive-strength = <0x00 0x70>;
		};

		gpio114_cfg_func: gpio114_cfg_func {
                     pinctrl-single,pins = <0xEC  0>;
                     pinctrl-single,bias-pulldown = <0 2 0 2>;
                     pinctrl-single,bias-pullup = <0 1 0 1>;
                     pinctrl-single,drive-strength = <0x00 0x70>;
		};
		gpio114_cfg_idle: gpio114_cfg_idle {
                     pinctrl-single,pins = <0xEC  0>;
                     pinctrl-single,bias-pulldown = <0 2 0 2>;
                     pinctrl-single,bias-pullup = <0 1 0 1>;
                     pinctrl-single,drive-strength = <0x00 0x70>;
		};

		gpio115_cfg_func: gpio115_cfg_func {
                     pinctrl-single,pins = <0xF0  0>;
                     pinctrl-single,bias-pulldown = <0 2 0 2>;
                     pinctrl-single,bias-pullup = <0 1 0 1>;
                     pinctrl-single,drive-strength = <0x00 0x70>;
		};
		gpio115_cfg_idle: gpio115_cfg_idle {
                     pinctrl-single,pins = <0xF0  0>;
                     pinctrl-single,bias-pulldown = <0 2 0 2>;
                     pinctrl-single,bias-pullup = <0 1 0 1>;
                     pinctrl-single,drive-strength = <0x00 0x70>;
		};

		gpio116_cfg_func: gpio116_cfg_func {
                     pinctrl-single,pins = <0xF4  0>;
                     pinctrl-single,bias-pulldown = <0 2 0 2>;
                     pinctrl-single,bias-pullup = <0 1 0 1>;
                     pinctrl-single,drive-strength = <0x00 0x70>;
		};
		gpio116_cfg_idle: gpio116_cfg_idle {
                     pinctrl-single,pins = <0xF4  0>;
                     pinctrl-single,bias-pulldown = <0 2 0 2>;
                     pinctrl-single,bias-pullup = <0 1 0 1>;
                     pinctrl-single,drive-strength = <0x00 0x70>;
		};

		gpio117_cfg_func: gpio117_cfg_func {
                     pinctrl-single,pins = <0xF8  0>;
                     pinctrl-single,bias-pulldown = <0 2 0 2>;
                     pinctrl-single,bias-pullup = <0 1 0 1>;
                     pinctrl-single,drive-strength = <0x00 0x70>;
		};
		gpio117_cfg_idle: gpio117_cfg_idle {
                     pinctrl-single,pins = <0xF8  0>;
                     pinctrl-single,bias-pulldown = <0 2 0 2>;
                     pinctrl-single,bias-pullup = <0 1 0 1>;
                     pinctrl-single,drive-strength = <0x00 0x70>;
		};

		gpio118_cfg_func: gpio118_cfg_func {
                     pinctrl-single,pins = <0xFC  0>;
                     pinctrl-single,bias-pulldown = <0 2 0 2>;
                     pinctrl-single,bias-pullup = <0 1 0 1>;
                     pinctrl-single,drive-strength = <0x00 0x70>;
		};
		gpio118_cfg_idle: gpio118_cfg_idle {
                     pinctrl-single,pins = <0xFC  0>;
                     pinctrl-single,bias-pulldown = <0 2 0 2>;
                     pinctrl-single,bias-pullup = <0 1 0 1>;
                     pinctrl-single,drive-strength = <0x00 0x70>;
		};

		gpio119_cfg_func: gpio119_cfg_func {
                     pinctrl-single,pins = <0x100  0>;
                     pinctrl-single,bias-pulldown = <0 2 0 2>;
                     pinctrl-single,bias-pullup = <0 1 0 1>;
                     pinctrl-single,drive-strength = <0x00 0x70>;
		};
		gpio119_cfg_idle: gpio119_cfg_idle {
                     pinctrl-single,pins = <0x100  0>;
                     pinctrl-single,bias-pulldown = <0 2 0 2>;
                     pinctrl-single,bias-pullup = <0 1 0 1>;
                     pinctrl-single,drive-strength = <0x00 0x70>;
		};

		EMMC_CLK_cfg_func: EMMC_CLK_cfg_func {
                     pinctrl-single,pins = <0x104  0>;
                     pinctrl-single,bias-pulldown = <0 2 0 2>;
                     pinctrl-single,bias-pullup = <0 1 0 1>;
                     pinctrl-single,drive-strength = <0x20 0x70>;
		};
		EMMC_CLK_cfg_idle: EMMC_CLK_cfg_idle {
                     pinctrl-single,pins = <0x104  0>;
                     pinctrl-single,bias-pulldown = <0 2 0 2>;
                     pinctrl-single,bias-pullup = <0 1 0 1>;
                     pinctrl-single,drive-strength = <0x20 0x70>;
		};

		EMMC_CMD_cfg_func: EMMC_CMD_cfg_func {
                     pinctrl-single,pins = <0x108  0>;
                     pinctrl-single,bias-pulldown = <0 2 0 2>;
                     pinctrl-single,bias-pullup = <1 1 0 1>;
                     pinctrl-single,drive-strength = <0x10 0x70>;
		};
		EMMC_CMD_cfg_idle: EMMC_CMD_cfg_idle {
                     pinctrl-single,pins = <0x108  0>;
                     pinctrl-single,bias-pulldown = <0 2 0 2>;
                     pinctrl-single,bias-pullup = <1 1 0 1>;
                     pinctrl-single,drive-strength = <0x10 0x70>;
		};

		EMMC_DATA0_cfg_func: EMMC_DATA0_cfg_func {
                     pinctrl-single,pins = <0x10C  0>;
                     pinctrl-single,bias-pulldown = <0 2 0 2>;
                     pinctrl-single,bias-pullup = <1 1 0 1>;
                     pinctrl-single,drive-strength = <0x10 0x70>;
		};
		EMMC_DATA0_cfg_idle: EMMC_DATA0_cfg_idle {
                     pinctrl-single,pins = <0x10C  0>;
                     pinctrl-single,bias-pulldown = <0 2 0 2>;
                     pinctrl-single,bias-pullup = <1 1 0 1>;
                     pinctrl-single,drive-strength = <0x10 0x70>;
		};

		EMMC_DATA1_cfg_func: EMMC_DATA1_cfg_func {
                     pinctrl-single,pins = <0x110  0>;
                     pinctrl-single,bias-pulldown = <0 2 0 2>;
                     pinctrl-single,bias-pullup = <1 1 0 1>;
                     pinctrl-single,drive-strength = <0x10 0x70>;
		};
		EMMC_DATA1_cfg_idle: EMMC_DATA1_cfg_idle {
                     pinctrl-single,pins = <0x110  0>;
                     pinctrl-single,bias-pulldown = <0 2 0 2>;
                     pinctrl-single,bias-pullup = <1 1 0 1>;
                     pinctrl-single,drive-strength = <0x10 0x70>;
		};

		EMMC_DATA2_cfg_func: EMMC_DATA2_cfg_func {
                     pinctrl-single,pins = <0x114  0>;
                     pinctrl-single,bias-pulldown = <0 2 0 2>;
                     pinctrl-single,bias-pullup = <1 1 0 1>;
                     pinctrl-single,drive-strength = <0x10 0x70>;
		};
		EMMC_DATA2_cfg_idle: EMMC_DATA2_cfg_idle {
                     pinctrl-single,pins = <0x114  0>;
                     pinctrl-single,bias-pulldown = <0 2 0 2>;
                     pinctrl-single,bias-pullup = <1 1 0 1>;
                     pinctrl-single,drive-strength = <0x10 0x70>;
		};

		EMMC_DATA3_cfg_func: EMMC_DATA3_cfg_func {
                     pinctrl-single,pins = <0x118  0>;
                     pinctrl-single,bias-pulldown = <0 2 0 2>;
                     pinctrl-single,bias-pullup = <1 1 0 1>;
                     pinctrl-single,drive-strength = <0x10 0x70>;
		};
		EMMC_DATA3_cfg_idle: EMMC_DATA3_cfg_idle {
                     pinctrl-single,pins = <0x118  0>;
                     pinctrl-single,bias-pulldown = <0 2 0 2>;
                     pinctrl-single,bias-pullup = <1 1 0 1>;
                     pinctrl-single,drive-strength = <0x10 0x70>;
		};

		EMMC_DATA4_cfg_func: EMMC_DATA4_cfg_func {
                     pinctrl-single,pins = <0x11C  0>;
                     pinctrl-single,bias-pulldown = <0 2 0 2>;
                     pinctrl-single,bias-pullup = <1 1 0 1>;
                     pinctrl-single,drive-strength = <0x10 0x70>;
		};
		EMMC_DATA4_cfg_idle: EMMC_DATA4_cfg_idle {
                     pinctrl-single,pins = <0x11C  0>;
                     pinctrl-single,bias-pulldown = <0 2 0 2>;
                     pinctrl-single,bias-pullup = <1 1 0 1>;
                     pinctrl-single,drive-strength = <0x10 0x70>;
		};

		EMMC_DATA5_cfg_func: EMMC_DATA5_cfg_func {
                     pinctrl-single,pins = <0x120  0>;
                     pinctrl-single,bias-pulldown = <0 2 0 2>;
                     pinctrl-single,bias-pullup = <1 1 0 1>;
                     pinctrl-single,drive-strength = <0x10 0x70>;
		};
		EMMC_DATA5_cfg_idle: EMMC_DATA5_cfg_idle {
                     pinctrl-single,pins = <0x120  0>;
                     pinctrl-single,bias-pulldown = <0 2 0 2>;
                     pinctrl-single,bias-pullup = <1 1 0 1>;
                     pinctrl-single,drive-strength = <0x10 0x70>;
		};

		EMMC_DATA6_cfg_func: EMMC_DATA6_cfg_func {
                     pinctrl-single,pins = <0x124  0>;
                     pinctrl-single,bias-pulldown = <0 2 0 2>;
                     pinctrl-single,bias-pullup = <1 1 0 1>;
                     pinctrl-single,drive-strength = <0x10 0x70>;
		};
		EMMC_DATA6_cfg_idle: EMMC_DATA6_cfg_idle {
                     pinctrl-single,pins = <0x124  0>;
                     pinctrl-single,bias-pulldown = <0 2 0 2>;
                     pinctrl-single,bias-pullup = <1 1 0 1>;
                     pinctrl-single,drive-strength = <0x10 0x70>;
		};

		EMMC_DATA7_cfg_func: EMMC_DATA7_cfg_func {
                     pinctrl-single,pins = <0x128  0>;
                     pinctrl-single,bias-pulldown = <0 2 0 2>;
                     pinctrl-single,bias-pullup = <1 1 0 1>;
                     pinctrl-single,drive-strength = <0x10 0x70>;
		};
		EMMC_DATA7_cfg_idle: EMMC_DATA7_cfg_idle {
                     pinctrl-single,pins = <0x128  0>;
                     pinctrl-single,bias-pulldown = <0 2 0 2>;
                     pinctrl-single,bias-pullup = <1 1 0 1>;
                     pinctrl-single,drive-strength = <0x10 0x70>;
		};

		EMMC_RST_N_cfg_func: EMMC_RST_N_cfg_func {
                     pinctrl-single,pins = <0x12C  0>;
                     pinctrl-single,bias-pulldown = <0 2 0 2>;
                     pinctrl-single,bias-pullup = <0 1 0 1>;
                     pinctrl-single,drive-strength = <0x10 0x70>;
		};
		EMMC_RST_N_cfg_idle: EMMC_RST_N_cfg_idle {
                     pinctrl-single,pins = <0x12C  0>;
                     pinctrl-single,bias-pulldown = <0 2 0 2>;
                     pinctrl-single,bias-pullup = <0 1 0 1>;
                     pinctrl-single,drive-strength = <0x10 0x70>;
		};

		gpio120_cfg_func: gpio120_cfg_func {
                     pinctrl-single,pins = <0x134  0>;
                     pinctrl-single,bias-pulldown = <0 2 0 2>;
                     pinctrl-single,bias-pullup = <0 1 0 1>;
                     pinctrl-single,drive-strength = <0x20 0x70>;
		};
		gpio120_cfg_idle: gpio120_cfg_idle {
                     pinctrl-single,pins = <0x134  0>;
                     pinctrl-single,bias-pulldown = <0 2 0 2>;
                     pinctrl-single,bias-pullup = <0 1 0 1>;
                     pinctrl-single,drive-strength = <0x00 0x70>;
		};

		gpio121_cfg_func: gpio121_cfg_func {
                     pinctrl-single,pins = <0x138  0>;
                     pinctrl-single,bias-pulldown = <0 2 0 2>;
                     pinctrl-single,bias-pullup = <1 1 0 1>;
                     pinctrl-single,drive-strength = <0x10 0x70>;
		};
		gpio121_cfg_idle: gpio121_cfg_idle {
                     pinctrl-single,pins = <0x138  0>;
                     pinctrl-single,bias-pulldown = <0 2 0 2>;
                     pinctrl-single,bias-pullup = <1 1 0 1>;
                     pinctrl-single,drive-strength = <0x00 0x70>;
		};

		gpio122_cfg_func: gpio122_cfg_func {
                     pinctrl-single,pins = <0x13C  0>;
                     pinctrl-single,bias-pulldown = <0 2 0 2>;
                     pinctrl-single,bias-pullup = <1 1 0 1>;
                     pinctrl-single,drive-strength = <0x10 0x70>;
		};
		gpio122_cfg_idle: gpio122_cfg_idle {
                     pinctrl-single,pins = <0x13C  0>;
                     pinctrl-single,bias-pulldown = <0 2 0 2>;
                     pinctrl-single,bias-pullup = <1 1 0 1>;
                     pinctrl-single,drive-strength = <0x00 0x70>;
		};

		gpio123_cfg_func: gpio123_cfg_func {
                     pinctrl-single,pins = <0x140  0>;
                     pinctrl-single,bias-pulldown = <0 2 0 2>;
                     pinctrl-single,bias-pullup = <1 1 0 1>;
                     pinctrl-single,drive-strength = <0x10 0x70>;
		};
		gpio123_cfg_idle: gpio123_cfg_idle {
                     pinctrl-single,pins = <0x140  0>;
                     pinctrl-single,bias-pulldown = <0 2 0 2>;
                     pinctrl-single,bias-pullup = <1 1 0 1>;
                     pinctrl-single,drive-strength = <0x00 0x70>;
		};

		gpio124_cfg_func: gpio124_cfg_func {
                     pinctrl-single,pins = <0x144  0>;
                     pinctrl-single,bias-pulldown = <0 2 0 2>;
                     pinctrl-single,bias-pullup = <1 1 0 1>;
                     pinctrl-single,drive-strength = <0x10 0x70>;
		};
		gpio124_cfg_idle: gpio124_cfg_idle {
                     pinctrl-single,pins = <0x144  0>;
                     pinctrl-single,bias-pulldown = <0 2 0 2>;
                     pinctrl-single,bias-pullup = <1 1 0 1>;
                     pinctrl-single,drive-strength = <0x00 0x70>;
		};

		gpio125_cfg_func: gpio125_cfg_func {
                     pinctrl-single,pins = <0x148  0>;
                     pinctrl-single,bias-pulldown = <0 2 0 2>;
                     pinctrl-single,bias-pullup = <1 1 0 1>;
                     pinctrl-single,drive-strength = <0x10 0x70>;
		};
		gpio125_cfg_idle: gpio125_cfg_idle {
                     pinctrl-single,pins = <0x148  0>;
                     pinctrl-single,bias-pulldown = <0 2 0 2>;
                     pinctrl-single,bias-pullup = <1 1 0 1>;
                     pinctrl-single,drive-strength = <0x00 0x70>;
		};

		gpio024_cfg_func: gpio024_cfg_func {
                     pinctrl-single,pins = <0x150  0>;
                     pinctrl-single,bias-pulldown = <0 2 0 2>;
                     pinctrl-single,bias-pullup = <1 1 0 1>;
                     pinctrl-single,drive-strength = <0x00 0x70>;
		};
		gpio024_cfg_idle: gpio024_cfg_idle {
                     pinctrl-single,pins = <0x150  0>;
                     pinctrl-single,bias-pulldown = <0 2 0 2>;
                     pinctrl-single,bias-pullup = <1 1 0 1>;
                     pinctrl-single,drive-strength = <0x00 0x70>;
		};

		gpio025_cfg_func: gpio025_cfg_func {
                     pinctrl-single,pins = <0x154  0>;
                     pinctrl-single,bias-pulldown = <2 2 0 2>;
                     pinctrl-single,bias-pullup = <0 1 0 1>;
                     pinctrl-single,drive-strength = <0x00 0x70>;
		};
		gpio025_cfg_idle: gpio025_cfg_idle {
                     pinctrl-single,pins = <0x154  0>;
                     pinctrl-single,bias-pulldown = <2 2 0 2>;
                     pinctrl-single,bias-pullup = <0 1 0 1>;
                     pinctrl-single,drive-strength = <0x00 0x70>;
		};

		gpio026_cfg_func: gpio026_cfg_func {
                     pinctrl-single,pins = <0x158  0>;
                     pinctrl-single,bias-pulldown = <2 2 0 2>;
                     pinctrl-single,bias-pullup = <0 1 0 1>;
                     pinctrl-single,drive-strength = <0x00 0x70>;
		};
		gpio026_cfg_idle: gpio026_cfg_idle {
                     pinctrl-single,pins = <0x158  0>;
                     pinctrl-single,bias-pulldown = <2 2 0 2>;
                     pinctrl-single,bias-pullup = <0 1 0 1>;
                     pinctrl-single,drive-strength = <0x00 0x70>;
		};

		gpio027_cfg_func: gpio027_cfg_func {
                     pinctrl-single,pins = <0x15C  0>;
                     pinctrl-single,bias-pulldown = <0 2 0 2>;
                     pinctrl-single,bias-pullup = <0 1 0 1>;
                     pinctrl-single,drive-strength = <0x00 0x70>;
		};
		gpio027_cfg_idle: gpio027_cfg_idle {
                     pinctrl-single,pins = <0x15C  0>;
                     pinctrl-single,bias-pulldown = <0 2 0 2>;
                     pinctrl-single,bias-pullup = <0 1 0 1>;
                     pinctrl-single,drive-strength = <0x00 0x70>;
		};

		gpio028_cfg_func: gpio028_cfg_func {
                     pinctrl-single,pins = <0x160  0>;
                     pinctrl-single,bias-pulldown = <0 2 0 2>;
                     pinctrl-single,bias-pullup = <0 1 0 1>;
                     pinctrl-single,drive-strength = <0x00 0x70>;
		};
		gpio028_cfg_idle: gpio028_cfg_idle {
                     pinctrl-single,pins = <0x160  0>;
                     pinctrl-single,bias-pulldown = <0 2 0 2>;
                     pinctrl-single,bias-pullup = <0 1 0 1>;
                     pinctrl-single,drive-strength = <0x00 0x70>;
		};

		gpio029_cfg_func: gpio029_cfg_func {
                     pinctrl-single,pins = <0x164  0>;
                     pinctrl-single,bias-pulldown = <0 2 0 2>;
                     pinctrl-single,bias-pullup = <0 1 0 1>;
                     pinctrl-single,drive-strength = <0x00 0x70>;
		};
		gpio029_cfg_idle: gpio029_cfg_idle {
                     pinctrl-single,pins = <0x164  0>;
                     pinctrl-single,bias-pulldown = <0 2 0 2>;
                     pinctrl-single,bias-pullup = <0 1 0 1>;
                     pinctrl-single,drive-strength = <0x00 0x70>;
		};

		gpio030_cfg_func: gpio030_cfg_func {
                     pinctrl-single,pins = <0x168  0>;
                     pinctrl-single,bias-pulldown = <2 2 0 2>;
                     pinctrl-single,bias-pullup = <0 1 0 1>;
                     pinctrl-single,drive-strength = <0x00 0x70>;
		};
		gpio030_cfg_idle: gpio030_cfg_idle {
                     pinctrl-single,pins = <0x168  0>;
                     pinctrl-single,bias-pulldown = <2 2 0 2>;
                     pinctrl-single,bias-pullup = <0 1 0 1>;
                     pinctrl-single,drive-strength = <0x00 0x70>;
		};

		gpio031_cfg_func: gpio031_cfg_func {
                     pinctrl-single,pins = <0x16C  0>;
                     pinctrl-single,bias-pulldown = <0 2 0 2>;
                     pinctrl-single,bias-pullup = <0 1 0 1>;
                     pinctrl-single,drive-strength = <0x00 0x70>;
		};
		gpio031_cfg_idle: gpio031_cfg_idle {
                     pinctrl-single,pins = <0x16C  0>;
                     pinctrl-single,bias-pulldown = <0 2 0 2>;
                     pinctrl-single,bias-pullup = <0 1 0 1>;
                     pinctrl-single,drive-strength = <0x00 0x70>;
		};

		gpio032_cfg_func: gpio032_cfg_func {
                     pinctrl-single,pins = <0x170  0>;
                     pinctrl-single,bias-pulldown = <0 2 0 2>;
                     pinctrl-single,bias-pullup = <0 1 0 1>;
                     pinctrl-single,drive-strength = <0x00 0x70>;
		};
		gpio032_cfg_idle: gpio032_cfg_idle {
                     pinctrl-single,pins = <0x170  0>;
                     pinctrl-single,bias-pulldown = <0 2 0 2>;
                     pinctrl-single,bias-pullup = <0 1 0 1>;
                     pinctrl-single,drive-strength = <0x00 0x70>;
		};

		gpio033_cfg_func: gpio033_cfg_func {
                     pinctrl-single,pins = <0x174  0>;
                     pinctrl-single,bias-pulldown = <0 2 0 2>;
                     pinctrl-single,bias-pullup = <0 1 0 1>;
                     pinctrl-single,drive-strength = <0x00 0x70>;
		};
		gpio033_cfg_idle: gpio033_cfg_idle {
                     pinctrl-single,pins = <0x174  0>;
                     pinctrl-single,bias-pulldown = <0 2 0 2>;
                     pinctrl-single,bias-pullup = <0 1 0 1>;
                     pinctrl-single,drive-strength = <0x00 0x70>;
		};

		gpio034_cfg_func: gpio034_cfg_func {
                     pinctrl-single,pins = <0x178  0>;
                     pinctrl-single,bias-pulldown = <0 2 0 2>;
                     pinctrl-single,bias-pullup = <0 1 0 1>;
                     pinctrl-single,drive-strength = <0x00 0x70>;
		};
		gpio034_cfg_idle: gpio034_cfg_idle {
                     pinctrl-single,pins = <0x178  0>;
                     pinctrl-single,bias-pulldown = <0 2 0 2>;
                     pinctrl-single,bias-pullup = <0 1 0 1>;
                     pinctrl-single,drive-strength = <0x00 0x70>;
		};

		gpio035_cfg_func: gpio035_cfg_func {
                     pinctrl-single,pins = <0x17C  0>;
                     pinctrl-single,bias-pulldown = <0 2 0 2>;
                     pinctrl-single,bias-pullup = <0 1 0 1>;
                     pinctrl-single,drive-strength = <0x00 0x70>;
		};
		gpio035_cfg_idle: gpio035_cfg_idle {
                     pinctrl-single,pins = <0x17C  0>;
                     pinctrl-single,bias-pulldown = <0 2 0 2>;
                     pinctrl-single,bias-pullup = <0 1 0 1>;
                     pinctrl-single,drive-strength = <0x00 0x70>;
		};

		gpio036_cfg_func: gpio036_cfg_func {
                     pinctrl-single,pins = <0x180  0>;
                     pinctrl-single,bias-pulldown = <0 2 0 2>;
                     pinctrl-single,bias-pullup = <0 1 0 1>;
                     pinctrl-single,drive-strength = <0x00 0x70>;
		};
		gpio036_cfg_idle: gpio036_cfg_idle {
                     pinctrl-single,pins = <0x180  0>;
                     pinctrl-single,bias-pulldown = <0 2 0 2>;
                     pinctrl-single,bias-pullup = <0 1 0 1>;
                     pinctrl-single,drive-strength = <0x00 0x70>;
		};

		gpio037_cfg_func: gpio037_cfg_func {
                     pinctrl-single,pins = <0x184  0>;
                     pinctrl-single,bias-pulldown = <0 2 0 2>;
                     pinctrl-single,bias-pullup = <0 1 0 1>;
                     pinctrl-single,drive-strength = <0x00 0x70>;
		};
		gpio037_cfg_idle: gpio037_cfg_idle {
                     pinctrl-single,pins = <0x184  0>;
                     pinctrl-single,bias-pulldown = <0 2 0 2>;
                     pinctrl-single,bias-pullup = <0 1 0 1>;
                     pinctrl-single,drive-strength = <0x00 0x70>;
		};

		gpio038_cfg_func: gpio038_cfg_func {
                     pinctrl-single,pins = <0x188  0>;
                     pinctrl-single,bias-pulldown = <2 2 0 2>;
                     pinctrl-single,bias-pullup = <0 1 0 1>;
                     pinctrl-single,drive-strength = <0x00 0x70>;
		};
		gpio038_cfg_idle: gpio038_cfg_idle {
                     pinctrl-single,pins = <0x188  0>;
                     pinctrl-single,bias-pulldown = <2 2 0 2>;
                     pinctrl-single,bias-pullup = <0 1 0 1>;
                     pinctrl-single,drive-strength = <0x00 0x70>;
		};

		gpio039_cfg_func: gpio039_cfg_func {
                     pinctrl-single,pins = <0x18C  0>;
                     pinctrl-single,bias-pulldown = <2 2 0 2>;
                     pinctrl-single,bias-pullup = <0 1 0 1>;
                     pinctrl-single,drive-strength = <0x00 0x70>;
		};
		gpio039_cfg_idle: gpio039_cfg_idle {
                     pinctrl-single,pins = <0x18C  0>;
                     pinctrl-single,bias-pulldown = <2 2 0 2>;
                     pinctrl-single,bias-pullup = <0 1 0 1>;
                     pinctrl-single,drive-strength = <0x00 0x70>;
		};

		gpio040_cfg_func: gpio040_cfg_func {
                     pinctrl-single,pins = <0x190  0>;
                     pinctrl-single,bias-pulldown = <2 2 0 2>;
                     pinctrl-single,bias-pullup = <0 1 0 1>;
                     pinctrl-single,drive-strength = <0x00 0x70>;
		};
		gpio040_cfg_idle: gpio040_cfg_idle {
                     pinctrl-single,pins = <0x190  0>;
                     pinctrl-single,bias-pulldown = <2 2 0 2>;
                     pinctrl-single,bias-pullup = <0 1 0 1>;
                     pinctrl-single,drive-strength = <0x00 0x70>;
		};

		gpio041_cfg_func: gpio041_cfg_func {
                     pinctrl-single,pins = <0x194  0>;
                     pinctrl-single,bias-pulldown = <2 2 0 2>;
                     pinctrl-single,bias-pullup = <0 1 0 1>;
                     pinctrl-single,drive-strength = <0x00 0x70>;
		};
		gpio041_cfg_idle: gpio041_cfg_idle {
                     pinctrl-single,pins = <0x194  0>;
                     pinctrl-single,bias-pulldown = <2 2 0 2>;
                     pinctrl-single,bias-pullup = <0 1 0 1>;
                     pinctrl-single,drive-strength = <0x00 0x70>;
		};

		gpio042_cfg_func: gpio042_cfg_func {
                     pinctrl-single,pins = <0x198  0>;
                     pinctrl-single,bias-pulldown = <2 2 0 2>;
                     pinctrl-single,bias-pullup = <0 1 0 1>;
                     pinctrl-single,drive-strength = <0x00 0x70>;
		};
		gpio042_cfg_idle: gpio042_cfg_idle {
                     pinctrl-single,pins = <0x198  0>;
                     pinctrl-single,bias-pulldown = <2 2 0 2>;
                     pinctrl-single,bias-pullup = <0 1 0 1>;
                     pinctrl-single,drive-strength = <0x00 0x70>;
		};

		gpio043_cfg_func: gpio043_cfg_func {
                     pinctrl-single,pins = <0x19C  0>;
                     pinctrl-single,bias-pulldown = <2 2 0 2>;
                     pinctrl-single,bias-pullup = <0 1 0 1>;
                     pinctrl-single,drive-strength = <0x00 0x70>;
		};
		gpio043_cfg_idle: gpio043_cfg_idle {
                     pinctrl-single,pins = <0x19C  0>;
                     pinctrl-single,bias-pulldown = <2 2 0 2>;
                     pinctrl-single,bias-pullup = <0 1 0 1>;
                     pinctrl-single,drive-strength = <0x00 0x70>;
		};

		gpio044_cfg_func: gpio044_cfg_func {
                     pinctrl-single,pins = <0x1A0  0>;
                     pinctrl-single,bias-pulldown = <0 2 0 2>;
                     pinctrl-single,bias-pullup = <0 1 0 1>;
                     pinctrl-single,drive-strength = <0x00 0x70>;
		};
		gpio044_cfg_idle: gpio044_cfg_idle {
                     pinctrl-single,pins = <0x1A0  0>;
                     pinctrl-single,bias-pulldown = <0 2 0 2>;
                     pinctrl-single,bias-pullup = <0 1 0 1>;
                     pinctrl-single,drive-strength = <0x00 0x70>;
		};

		gpio045_cfg_func: gpio045_cfg_func {
                     pinctrl-single,pins = <0x1A4  0>;
                     pinctrl-single,bias-pulldown = <2 2 0 2>;
                     pinctrl-single,bias-pullup = <0 1 0 1>;
                     pinctrl-single,drive-strength = <0x00 0x70>;
		};
		gpio045_cfg_idle: gpio045_cfg_idle {
                     pinctrl-single,pins = <0x1A4  0>;
                     pinctrl-single,bias-pulldown = <2 2 0 2>;
                     pinctrl-single,bias-pullup = <0 1 0 1>;
                     pinctrl-single,drive-strength = <0x00 0x70>;
		};

		gpio046_cfg_func: gpio046_cfg_func {
                     pinctrl-single,pins = <0x1A8  0>;
                     pinctrl-single,bias-pulldown = <2 2 0 2>;
                     pinctrl-single,bias-pullup = <0 1 0 1>;
                     pinctrl-single,drive-strength = <0x00 0x70>;
		};
		gpio046_cfg_idle: gpio046_cfg_idle {
                     pinctrl-single,pins = <0x1A8  0>;
                     pinctrl-single,bias-pulldown = <2 2 0 2>;
                     pinctrl-single,bias-pullup = <0 1 0 1>;
                     pinctrl-single,drive-strength = <0x00 0x70>;
		};

		gpio047_cfg_func: gpio047_cfg_func {
                     pinctrl-single,pins = <0x1AC  0>;
                     pinctrl-single,bias-pulldown = <2 2 0 2>;
                     pinctrl-single,bias-pullup = <0 1 0 1>;
                     pinctrl-single,drive-strength = <0x00 0x70>;
		};
		gpio047_cfg_idle: gpio047_cfg_idle {
                     pinctrl-single,pins = <0x1AC  0>;
                     pinctrl-single,bias-pulldown = <2 2 0 2>;
                     pinctrl-single,bias-pullup = <0 1 0 1>;
                     pinctrl-single,drive-strength = <0x00 0x70>;
		};

		gpio048_cfg_func: gpio048_cfg_func {
                     pinctrl-single,pins = <0x1B0  0>;
                     pinctrl-single,bias-pulldown = <2 2 0 2>;
                     pinctrl-single,bias-pullup = <0 1 0 1>;
                     pinctrl-single,drive-strength = <0x00 0x70>;
		};
		gpio048_cfg_idle: gpio048_cfg_idle {
                     pinctrl-single,pins = <0x1B0  0>;
                     pinctrl-single,bias-pulldown = <2 2 0 2>;
                     pinctrl-single,bias-pullup = <0 1 0 1>;
                     pinctrl-single,drive-strength = <0x00 0x70>;
		};

		gpio049_cfg_func: gpio049_cfg_func {
                     pinctrl-single,pins = <0x1B4  0>;
                     pinctrl-single,bias-pulldown = <2 2 0 2>;
                     pinctrl-single,bias-pullup = <0 1 0 1>;
                     pinctrl-single,drive-strength = <0x00 0x70>;
		};
		gpio049_cfg_idle: gpio049_cfg_idle {
                     pinctrl-single,pins = <0x1B4  0>;
                     pinctrl-single,bias-pulldown = <2 2 0 2>;
                     pinctrl-single,bias-pullup = <0 1 0 1>;
                     pinctrl-single,drive-strength = <0x00 0x70>;
		};

		gpio050_cfg_func: gpio050_cfg_func {
                     pinctrl-single,pins = <0x1B8  0>;
                     pinctrl-single,bias-pulldown = <2 2 0 2>;
                     pinctrl-single,bias-pullup = <0 1 0 1>;
                     pinctrl-single,drive-strength = <0x00 0x70>;
		};
		gpio050_cfg_idle: gpio050_cfg_idle {
                     pinctrl-single,pins = <0x1B8  0>;
                     pinctrl-single,bias-pulldown = <2 2 0 2>;
                     pinctrl-single,bias-pullup = <0 1 0 1>;
                     pinctrl-single,drive-strength = <0x00 0x70>;
		};

		gpio051_cfg_func: gpio051_cfg_func {
                     pinctrl-single,pins = <0x1BC  0>;
                     pinctrl-single,bias-pulldown = <2 2 0 2>;
                     pinctrl-single,bias-pullup = <0 1 0 1>;
                     pinctrl-single,drive-strength = <0x00 0x70>;
		};
		gpio051_cfg_idle: gpio051_cfg_idle {
                     pinctrl-single,pins = <0x1BC  0>;
                     pinctrl-single,bias-pulldown = <2 2 0 2>;
                     pinctrl-single,bias-pullup = <0 1 0 1>;
                     pinctrl-single,drive-strength = <0x00 0x70>;
		};

		gpio052_cfg_func: gpio052_cfg_func {
                     pinctrl-single,pins = <0x1C0  0>;
                     pinctrl-single,bias-pulldown = <2 2 0 2>;
                     pinctrl-single,bias-pullup = <0 1 0 1>;
                     pinctrl-single,drive-strength = <0x00 0x70>;
		};
		gpio052_cfg_idle: gpio052_cfg_idle {
                     pinctrl-single,pins = <0x1C0  0>;
                     pinctrl-single,bias-pulldown = <2 2 0 2>;
                     pinctrl-single,bias-pullup = <0 1 0 1>;
                     pinctrl-single,drive-strength = <0x00 0x70>;
		};

		gpio053_cfg_func: gpio053_cfg_func {
                     pinctrl-single,pins = <0x1C4  0>;
                     pinctrl-single,bias-pulldown = <2 2 0 2>;
                     pinctrl-single,bias-pullup = <0 1 0 1>;
                     pinctrl-single,drive-strength = <0x00 0x70>;
		};
		gpio053_cfg_idle: gpio053_cfg_idle {
                     pinctrl-single,pins = <0x1C4  0>;
                     pinctrl-single,bias-pulldown = <2 2 0 2>;
                     pinctrl-single,bias-pullup = <0 1 0 1>;
                     pinctrl-single,drive-strength = <0x00 0x70>;
		};

		gpio054_cfg_func: gpio054_cfg_func {
                     pinctrl-single,pins = <0x1C8  0>;
                     pinctrl-single,bias-pulldown = <0 2 0 2>;
                     pinctrl-single,bias-pullup = <0 1 0 1>;
                     pinctrl-single,drive-strength = <0x00 0x70>;
		};
		gpio054_cfg_idle: gpio054_cfg_idle {
                     pinctrl-single,pins = <0x1C8  0>;
                     pinctrl-single,bias-pulldown = <2 2 0 2>;
                     pinctrl-single,bias-pullup = <0 1 0 1>;
                     pinctrl-single,drive-strength = <0x00 0x70>;
		};

		gpio055_cfg_func: gpio055_cfg_func {
                     pinctrl-single,pins = <0x1CC  0>;
                     pinctrl-single,bias-pulldown = <2 2 0 2>;
                     pinctrl-single,bias-pullup = <0 1 0 1>;
                     pinctrl-single,drive-strength = <0x00 0x70>;
		};
		gpio055_cfg_idle: gpio055_cfg_idle {
                     pinctrl-single,pins = <0x1CC  0>;
                     pinctrl-single,bias-pulldown = <2 2 0 2>;
                     pinctrl-single,bias-pullup = <0 1 0 1>;
                     pinctrl-single,drive-strength = <0x00 0x70>;
		};

		gpio056_cfg_func: gpio056_cfg_func {
                     pinctrl-single,pins = <0x1D0  0>;
                     pinctrl-single,bias-pulldown = <0 2 0 2>;
                     pinctrl-single,bias-pullup = <0 1 0 1>;
                     pinctrl-single,drive-strength = <0x00 0x70>;
		};
		gpio056_cfg_idle: gpio056_cfg_idle {
                     pinctrl-single,pins = <0x1D0  0>;
                     pinctrl-single,bias-pulldown = <2 2 0 2>;
                     pinctrl-single,bias-pullup = <0 1 0 1>;
                     pinctrl-single,drive-strength = <0x00 0x70>;
		};

		gpio057_cfg_func: gpio057_cfg_func {
                     pinctrl-single,pins = <0x1D4  0>;
                     pinctrl-single,bias-pulldown = <0 2 0 2>;
                     pinctrl-single,bias-pullup = <1 1 0 1>;
                     pinctrl-single,drive-strength = <0x00 0x70>;
		};
		gpio057_cfg_idle: gpio057_cfg_idle {
                     pinctrl-single,pins = <0x1D4  0>;
                     pinctrl-single,bias-pulldown = <0 2 0 2>;
                     pinctrl-single,bias-pullup = <1 1 0 1>;
                     pinctrl-single,drive-strength = <0x00 0x70>;
		};

		gpio060_cfg_func: gpio060_cfg_func {
                     pinctrl-single,pins = <0x1E0  0>;
                     pinctrl-single,bias-pulldown = <2 2 0 2>;
                     pinctrl-single,bias-pullup = <0 1 0 1>;
                     pinctrl-single,drive-strength = <0x00 0x70>;
		};
		gpio060_cfg_idle: gpio060_cfg_idle {
                     pinctrl-single,pins = <0x1E0  0>;
                     pinctrl-single,bias-pulldown = <2 2 0 2>;
                     pinctrl-single,bias-pullup = <0 1 0 1>;
                     pinctrl-single,drive-strength = <0x00 0x70>;
		};

		gpio061_cfg_func: gpio061_cfg_func {
                     pinctrl-single,pins = <0x1E4  0>;
                     pinctrl-single,bias-pulldown = <2 2 0 2>;
                     pinctrl-single,bias-pullup = <0 1 0 1>;
                     pinctrl-single,drive-strength = <0x00 0x70>;
		};
		gpio061_cfg_idle: gpio061_cfg_idle {
                     pinctrl-single,pins = <0x1E4  0>;
                     pinctrl-single,bias-pulldown = <2 2 0 2>;
                     pinctrl-single,bias-pullup = <0 1 0 1>;
                     pinctrl-single,drive-strength = <0x00 0x70>;
		};

		gpio062_cfg_func: gpio062_cfg_func {
                     pinctrl-single,pins = <0x1E8  0>;
                     pinctrl-single,bias-pulldown = <0 2 0 2>;
                     pinctrl-single,bias-pullup = <1 1 0 1>;
                     pinctrl-single,drive-strength = <0x00 0x70>;
		};
		gpio062_cfg_idle: gpio062_cfg_idle {
                     pinctrl-single,pins = <0x1E8  0>;
                     pinctrl-single,bias-pulldown = <0 2 0 2>;
                     pinctrl-single,bias-pullup = <1 1 0 1>;
                     pinctrl-single,drive-strength = <0x00 0x70>;
		};

		gpio063_cfg_func: gpio063_cfg_func {
                     pinctrl-single,pins = <0x1EC  0>;
                     pinctrl-single,bias-pulldown = <0 2 0 2>;
                     pinctrl-single,bias-pullup = <0 1 0 1>;
                     pinctrl-single,drive-strength = <0x00 0x70>;
		};
		gpio063_cfg_idle: gpio063_cfg_idle {
                     pinctrl-single,pins = <0x1EC  0>;
                     pinctrl-single,bias-pulldown = <0 2 0 2>;
                     pinctrl-single,bias-pullup = <0 1 0 1>;
                     pinctrl-single,drive-strength = <0x00 0x70>;
		};

		gpio064_cfg_func: gpio064_cfg_func {
                     pinctrl-single,pins = <0x1F0  0>;
                     pinctrl-single,bias-pulldown = <0 2 0 2>;
                     pinctrl-single,bias-pullup = <0 1 0 1>;
                     pinctrl-single,drive-strength = <0x00 0x70>;
		};
		gpio064_cfg_idle: gpio064_cfg_idle {
                     pinctrl-single,pins = <0x1F0  0>;
                     pinctrl-single,bias-pulldown = <0 2 0 2>;
                     pinctrl-single,bias-pullup = <0 1 0 1>;
                     pinctrl-single,drive-strength = <0x00 0x70>;
		};

		gpio065_cfg_func: gpio065_cfg_func {
                     pinctrl-single,pins = <0x1F4  0>;
                     pinctrl-single,bias-pulldown = <2 2 0 2>;
                     pinctrl-single,bias-pullup = <0 1 0 1>;
                     pinctrl-single,drive-strength = <0x00 0x70>;
		};
		gpio065_cfg_idle: gpio065_cfg_idle {
                     pinctrl-single,pins = <0x1F4  0>;
                     pinctrl-single,bias-pulldown = <2 2 0 2>;
                     pinctrl-single,bias-pullup = <0 1 0 1>;
                     pinctrl-single,drive-strength = <0x00 0x70>;
		};

       };

    pmx2: pinmux@F8001800 {
		RSTOUT_N_cfg_func: RSTOUT_N_cfg_func {
                     pinctrl-single,pins = <0x0  0>;
                     pinctrl-single,bias-pulldown = <0 2 0 2>;
                     pinctrl-single,bias-pullup = <0 1 0 1>;
                     pinctrl-single,drive-strength = <0x00 0x70>;
		};
		RSTOUT_N_cfg_idle: RSTOUT_N_cfg_idle {
                     pinctrl-single,pins = <0x0  0>;
                     pinctrl-single,bias-pulldown = <0 2 0 2>;
                     pinctrl-single,bias-pullup = <0 1 0 1>;
                     pinctrl-single,drive-strength = <0x00 0x70>;
		};

		PMU_PERI_EN_cfg_func: PMU_PERI_EN_cfg_func {
                     pinctrl-single,pins = <0x4  0>;
                     pinctrl-single,bias-pulldown = <0 2 0 2>;
                     pinctrl-single,bias-pullup = <0 1 0 1>;
                     pinctrl-single,drive-strength = <0x00 0x70>;
		};
		PMU_PERI_EN_cfg_idle: PMU_PERI_EN_cfg_idle {
                     pinctrl-single,pins = <0x4  0>;
                     pinctrl-single,bias-pulldown = <0 2 0 2>;
                     pinctrl-single,bias-pullup = <0 1 0 1>;
                     pinctrl-single,drive-strength = <0x00 0x70>;
		};

		SYSCLK0_EN_cfg_func: SYSCLK0_EN_cfg_func {
                     pinctrl-single,pins = <0x8  0>;
                     pinctrl-single,bias-pulldown = <0 2 0 2>;
                     pinctrl-single,bias-pullup = <0 1 0 1>;
                     pinctrl-single,drive-strength = <0x00 0x70>;
		};
		SYSCLK0_EN_cfg_idle: SYSCLK0_EN_cfg_idle {
                     pinctrl-single,pins = <0x8  0>;
                     pinctrl-single,bias-pulldown = <0 2 0 2>;
                     pinctrl-single,bias-pullup = <0 1 0 1>;
                     pinctrl-single,drive-strength = <0x00 0x70>;
		};

		JTAG_TDO_cfg_func: JTAG_TDO_cfg_func {
                     pinctrl-single,pins = <0xC  0>;
                     pinctrl-single,bias-pulldown = <0 2 0 2>;
                     pinctrl-single,bias-pullup = <0 1 0 1>;
                     pinctrl-single,drive-strength = <0x20 0x70>;
		};
		JTAG_TDO_cfg_idle: JTAG_TDO_cfg_idle {
                     pinctrl-single,pins = <0xC  0>;
                     pinctrl-single,bias-pulldown = <0 2 0 2>;
                     pinctrl-single,bias-pullup = <0 1 0 1>;
                     pinctrl-single,drive-strength = <0x20 0x70>;
		};

		gpio000_cfg_func: gpio000_cfg_func {
                     pinctrl-single,pins = <0x10  0>;
                     pinctrl-single,bias-pulldown = <0 2 0 2>;
                     pinctrl-single,bias-pullup = <0 1 0 1>;
                     pinctrl-single,drive-strength = <0x00 0x70>;
		};
		gpio000_cfg_idle: gpio000_cfg_idle {
                     pinctrl-single,pins = <0x10  0>;
                     pinctrl-single,bias-pulldown = <0 2 0 2>;
                     pinctrl-single,bias-pullup = <0 1 0 1>;
                     pinctrl-single,drive-strength = <0x00 0x70>;
		};

		gpio001_cfg_func: gpio001_cfg_func {
                     pinctrl-single,pins = <0x14  0>;
                     pinctrl-single,bias-pulldown = <0 2 0 2>;
                     pinctrl-single,bias-pullup = <0 1 0 1>;
                     pinctrl-single,drive-strength = <0x00 0x70>;
		};
		gpio001_cfg_idle: gpio001_cfg_idle {
                     pinctrl-single,pins = <0x14  0>;
                     pinctrl-single,bias-pulldown = <0 2 0 2>;
                     pinctrl-single,bias-pullup = <0 1 0 1>;
                     pinctrl-single,drive-strength = <0x00 0x70>;
		};

		gpio002_cfg_func: gpio002_cfg_func {
                     pinctrl-single,pins = <0x18  0>;
                     pinctrl-single,bias-pulldown = <0 2 0 2>;
                     pinctrl-single,bias-pullup = <0 1 0 1>;
                     pinctrl-single,drive-strength = <0x00 0x70>;
		};
		gpio002_cfg_idle: gpio002_cfg_idle {
                     pinctrl-single,pins = <0x18  0>;
                     pinctrl-single,bias-pulldown = <0 2 0 2>;
                     pinctrl-single,bias-pullup = <0 1 0 1>;
                     pinctrl-single,drive-strength = <0x00 0x70>;
		};

		gpio003_cfg_func: gpio003_cfg_func {
                     pinctrl-single,pins = <0x1C  0>;
                     pinctrl-single,bias-pulldown = <2 2 0 2>;
                     pinctrl-single,bias-pullup = <0 1 0 1>;
                     pinctrl-single,drive-strength = <0x00 0x70>;
		};
		gpio003_cfg_idle: gpio003_cfg_idle {
                     pinctrl-single,pins = <0x1C  0>;
                     pinctrl-single,bias-pulldown = <2 2 0 2>;
                     pinctrl-single,bias-pullup = <0 1 0 1>;
                     pinctrl-single,drive-strength = <0x00 0x70>;
		};

		gpio004_cfg_func: gpio004_cfg_func {
                     pinctrl-single,pins = <0x20  0>;
                     pinctrl-single,bias-pulldown = <0 2 0 2>;
                     pinctrl-single,bias-pullup = <1 1 0 1>;
                     pinctrl-single,drive-strength = <0x00 0x70>;
		};
		gpio004_cfg_idle: gpio004_cfg_idle {
                     pinctrl-single,pins = <0x20  0>;
                     pinctrl-single,bias-pulldown = <0 2 0 2>;
                     pinctrl-single,bias-pullup = <1 1 0 1>;
                     pinctrl-single,drive-strength = <0x00 0x70>;
		};

		gpio005_cfg_func: gpio005_cfg_func {
                     pinctrl-single,pins = <0x24  0>;
                     pinctrl-single,bias-pulldown = <0 2 0 2>;
                     pinctrl-single,bias-pullup = <0 1 0 1>;
                     pinctrl-single,drive-strength = <0x00 0x70>;
		};
		gpio005_cfg_idle: gpio005_cfg_idle {
                     pinctrl-single,pins = <0x24  0>;
                     pinctrl-single,bias-pulldown = <0 2 0 2>;
                     pinctrl-single,bias-pullup = <0 1 0 1>;
                     pinctrl-single,drive-strength = <0x00 0x70>;
		};

		gpio006_cfg_func: gpio006_cfg_func {
                     pinctrl-single,pins = <0x28  0>;
                     pinctrl-single,bias-pulldown = <0 2 0 2>;
                     pinctrl-single,bias-pullup = <0 1 0 1>;
                     pinctrl-single,drive-strength = <0x00 0x70>;
		};
		gpio006_cfg_idle: gpio006_cfg_idle {
                     pinctrl-single,pins = <0x28  0>;
                     pinctrl-single,bias-pulldown = <0 2 0 2>;
                     pinctrl-single,bias-pullup = <0 1 0 1>;
                     pinctrl-single,drive-strength = <0x00 0x70>;
		};

		gpio007_cfg_func: gpio007_cfg_func {
                     pinctrl-single,pins = <0x2C  0>;
                     pinctrl-single,bias-pulldown = <0 2 0 2>;
                     pinctrl-single,bias-pullup = <1 1 0 1>;
                     pinctrl-single,drive-strength = <0x00 0x70>;
		};
		gpio007_cfg_idle: gpio007_cfg_idle {
                     pinctrl-single,pins = <0x2C  0>;
                     pinctrl-single,bias-pulldown = <0 2 0 2>;
                     pinctrl-single,bias-pullup = <1 1 0 1>;
                     pinctrl-single,drive-strength = <0x00 0x70>;
		};

		gpio008_cfg_func: gpio008_cfg_func {
                     pinctrl-single,pins = <0x30  0>;
                     pinctrl-single,bias-pulldown = <0 2 0 2>;
                     pinctrl-single,bias-pullup = <1 1 0 1>;
                     pinctrl-single,drive-strength = <0x00 0x70>;
		};
		gpio008_cfg_idle: gpio008_cfg_idle {
                     pinctrl-single,pins = <0x30  0>;
                     pinctrl-single,bias-pulldown = <0 2 0 2>;
                     pinctrl-single,bias-pullup = <1 1 0 1>;
                     pinctrl-single,drive-strength = <0x00 0x70>;
		};

		gpio009_cfg_func: gpio009_cfg_func {
                     pinctrl-single,pins = <0x34  0>;
                     pinctrl-single,bias-pulldown = <2 2 0 2>;
                     pinctrl-single,bias-pullup = <0 1 0 1>;
                     pinctrl-single,drive-strength = <0x00 0x70>;
		};
		gpio009_cfg_idle: gpio009_cfg_idle {
                     pinctrl-single,pins = <0x34  0>;
                     pinctrl-single,bias-pulldown = <2 2 0 2>;
                     pinctrl-single,bias-pullup = <0 1 0 1>;
                     pinctrl-single,drive-strength = <0x00 0x70>;
		};

		gpio010_cfg_func: gpio010_cfg_func {
                     pinctrl-single,pins = <0x38  0>;
                     pinctrl-single,bias-pulldown = <0 2 0 2>;
                     pinctrl-single,bias-pullup = <0 1 0 1>;
                     pinctrl-single,drive-strength = <0x00 0x70>;
		};
		gpio010_cfg_idle: gpio010_cfg_idle {
                     pinctrl-single,pins = <0x38  0>;
                     pinctrl-single,bias-pulldown = <2 2 0 2>;
                     pinctrl-single,bias-pullup = <0 1 0 1>;
                     pinctrl-single,drive-strength = <0x00 0x70>;
		};

		gpio011_cfg_func: gpio011_cfg_func {
                     pinctrl-single,pins = <0x3C  0>;
                     pinctrl-single,bias-pulldown = <0 2 0 2>;
                     pinctrl-single,bias-pullup = <0 1 0 1>;
                     pinctrl-single,drive-strength = <0x00 0x70>;
		};
		gpio011_cfg_idle: gpio011_cfg_idle {
                     pinctrl-single,pins = <0x3C  0>;
                     pinctrl-single,bias-pulldown = <2 2 0 2>;
                     pinctrl-single,bias-pullup = <0 1 0 1>;
                     pinctrl-single,drive-strength = <0x00 0x70>;
		};

		gpio012_cfg_func: gpio012_cfg_func {
                     pinctrl-single,pins = <0x40  0>;
                     pinctrl-single,bias-pulldown = <0 2 0 2>;
                     pinctrl-single,bias-pullup = <0 1 0 1>;
                     pinctrl-single,drive-strength = <0x00 0x70>;
		};
		gpio012_cfg_idle: gpio012_cfg_idle {
                     pinctrl-single,pins = <0x40  0>;
                     pinctrl-single,bias-pulldown = <2 2 0 2>;
                     pinctrl-single,bias-pullup = <0 1 0 1>;
                     pinctrl-single,drive-strength = <0x00 0x70>;
		};

		gpio013_cfg_func: gpio013_cfg_func {
                     pinctrl-single,pins = <0x44  0>;
                     pinctrl-single,bias-pulldown = <2 2 0 2>;
                     pinctrl-single,bias-pullup = <0 1 0 1>;
                     pinctrl-single,drive-strength = <0x00 0x70>;
		};
		gpio013_cfg_idle: gpio013_cfg_idle {
                     pinctrl-single,pins = <0x44  0>;
                     pinctrl-single,bias-pulldown = <2 2 0 2>;
                     pinctrl-single,bias-pullup = <0 1 0 1>;
                     pinctrl-single,drive-strength = <0x00 0x70>;
		};

		gpio014_cfg_func: gpio014_cfg_func {
                     pinctrl-single,pins = <0x48  0>;
                     pinctrl-single,bias-pulldown = <0 2 0 2>;
                     pinctrl-single,bias-pullup = <1 1 0 1>;
                     pinctrl-single,drive-strength = <0x00 0x70>;
		};
		gpio014_cfg_idle: gpio014_cfg_idle {
                     pinctrl-single,pins = <0x48  0>;
                     pinctrl-single,bias-pulldown = <0 2 0 2>;
                     pinctrl-single,bias-pullup = <1 1 0 1>;
                     pinctrl-single,drive-strength = <0x00 0x70>;
		};

		gpio015_cfg_func: gpio015_cfg_func {
                     pinctrl-single,pins = <0x4C  0>;
                     pinctrl-single,bias-pulldown = <0 2 0 2>;
                     pinctrl-single,bias-pullup = <1 1 0 1>;
                     pinctrl-single,drive-strength = <0x00 0x70>;
		};
		gpio015_cfg_idle: gpio015_cfg_idle {
                     pinctrl-single,pins = <0x4C  0>;
                     pinctrl-single,bias-pulldown = <0 2 0 2>;
                     pinctrl-single,bias-pullup = <1 1 0 1>;
                     pinctrl-single,drive-strength = <0x00 0x70>;
		};

		gpio016_cfg_func: gpio016_cfg_func {
                     pinctrl-single,pins = <0x50  0>;
                     pinctrl-single,bias-pulldown = <0 2 0 2>;
                     pinctrl-single,bias-pullup = <0 1 0 1>;
                     pinctrl-single,drive-strength = <0x00 0x70>;
		};
		gpio016_cfg_idle: gpio016_cfg_idle {
                     pinctrl-single,pins = <0x50  0>;
                     pinctrl-single,bias-pulldown = <0 2 0 2>;
                     pinctrl-single,bias-pullup = <0 1 0 1>;
                     pinctrl-single,drive-strength = <0x00 0x70>;
		};

		gpio017_cfg_func: gpio017_cfg_func {
                     pinctrl-single,pins = <0x54  0>;
                     pinctrl-single,bias-pulldown = <0 2 0 2>;
                     pinctrl-single,bias-pullup = <0 1 0 1>;
                     pinctrl-single,drive-strength = <0x00 0x70>;
		};
		gpio017_cfg_idle: gpio017_cfg_idle {
                     pinctrl-single,pins = <0x54  0>;
                     pinctrl-single,bias-pulldown = <0 2 0 2>;
                     pinctrl-single,bias-pullup = <0 1 0 1>;
                     pinctrl-single,drive-strength = <0x00 0x70>;
		};

		gpio018_cfg_func: gpio018_cfg_func {
                     pinctrl-single,pins = <0x58  0>;
                     pinctrl-single,bias-pulldown = <0 2 0 2>;
                     pinctrl-single,bias-pullup = <0 1 0 1>;
                     pinctrl-single,drive-strength = <0x00 0x70>;
		};
		gpio018_cfg_idle: gpio018_cfg_idle {
                     pinctrl-single,pins = <0x58  0>;
                     pinctrl-single,bias-pulldown = <0 2 0 2>;
                     pinctrl-single,bias-pullup = <0 1 0 1>;
                     pinctrl-single,drive-strength = <0x00 0x70>;
		};

		gpio019_cfg_func: gpio019_cfg_func {
                     pinctrl-single,pins = <0x5C  0>;
                     pinctrl-single,bias-pulldown = <0 2 0 2>;
                     pinctrl-single,bias-pullup = <0 1 0 1>;
                     pinctrl-single,drive-strength = <0x00 0x70>;
		};
		gpio019_cfg_idle: gpio019_cfg_idle {
                     pinctrl-single,pins = <0x5C  0>;
                     pinctrl-single,bias-pulldown = <0 2 0 2>;
                     pinctrl-single,bias-pullup = <0 1 0 1>;
                     pinctrl-single,drive-strength = <0x00 0x70>;
		};

		gpio020_cfg_func: gpio020_cfg_func {
                     pinctrl-single,pins = <0x60  0>;
                     pinctrl-single,bias-pulldown = <0 2 0 2>;
                     pinctrl-single,bias-pullup = <0 1 0 1>;
                     pinctrl-single,drive-strength = <0x00 0x70>;
		};
		gpio020_cfg_idle: gpio020_cfg_idle {
                     pinctrl-single,pins = <0x60  0>;
                     pinctrl-single,bias-pulldown = <0 2 0 2>;
                     pinctrl-single,bias-pullup = <0 1 0 1>;
                     pinctrl-single,drive-strength = <0x00 0x70>;
		};

		gpio021_cfg_func: gpio021_cfg_func {
                     pinctrl-single,pins = <0x64  0>;
                     pinctrl-single,bias-pulldown = <0 2 0 2>;
                     pinctrl-single,bias-pullup = <0 1 0 1>;
                     pinctrl-single,drive-strength = <0x00 0x70>;
		};
		gpio021_cfg_idle: gpio021_cfg_idle {
                     pinctrl-single,pins = <0x64  0>;
                     pinctrl-single,bias-pulldown = <0 2 0 2>;
                     pinctrl-single,bias-pullup = <0 1 0 1>;
                     pinctrl-single,drive-strength = <0x00 0x70>;
		};

		gpio022_cfg_func: gpio022_cfg_func {
                     pinctrl-single,pins = <0x68  0>;
                     pinctrl-single,bias-pulldown = <2 2 0 2>;
                     pinctrl-single,bias-pullup = <0 1 0 1>;
                     pinctrl-single,drive-strength = <0x00 0x70>;
		};
		gpio022_cfg_idle: gpio022_cfg_idle {
                     pinctrl-single,pins = <0x68  0>;
                     pinctrl-single,bias-pulldown = <2 2 0 2>;
                     pinctrl-single,bias-pullup = <0 1 0 1>;
                     pinctrl-single,drive-strength = <0x00 0x70>;
		};

		RF_RESET0_cfg_func: RF_RESET0_cfg_func {
                     pinctrl-single,pins = <0x70  0>;
                     pinctrl-single,bias-pulldown = <0 2 0 2>;
                     pinctrl-single,bias-pullup = <0 1 0 1>;
                     pinctrl-single,drive-strength = <0x00 0x70>;
		};
		RF_RESET0_cfg_idle: RF_RESET0_cfg_idle {
                     pinctrl-single,pins = <0x70  0>;
                     pinctrl-single,bias-pulldown = <0 2 0 2>;
                     pinctrl-single,bias-pullup = <0 1 0 1>;
                     pinctrl-single,drive-strength = <0x00 0x70>;
		};

		RF_RESET1_cfg_func: RF_RESET1_cfg_func {
                     pinctrl-single,pins = <0x74  0>;
                     pinctrl-single,bias-pulldown = <0 2 0 2>;
                     pinctrl-single,bias-pullup = <0 1 0 1>;
                     pinctrl-single,drive-strength = <0x00 0x70>;
		};
		RF_RESET1_cfg_idle: RF_RESET1_cfg_idle {
                     pinctrl-single,pins = <0x74  0>;
                     pinctrl-single,bias-pulldown = <0 2 0 2>;
                     pinctrl-single,bias-pullup = <0 1 0 1>;
                     pinctrl-single,drive-strength = <0x00 0x70>;
		};

       };
};
